VERSION "HIPBNYYYYYYYYYYYYYYYYYYYYYYYYYYYYYYYYYYYYY/4/%%%/4/'%**4YYY///"

NS_ :

BS_:

BU_: Equipment

BO_ 3221225472 VECTOR__INDEPENDENT_SIG_MSG: 0 Vector__XXX
 SG_ EngineExhaustGasRecirculation : 0|16@1+ (0.05,0) [0|3212.75] "kg/h" Vector__XXX
 SG_ ContlyMonitoredSyssEnabledComple : 0|8@1+ (8,0) [0|128] "" Vector__XXX

BO_ 257 CANSTD2: 8 Vector__XXX

BO_ 256 CANSTD1: 8 Vector__XXX
 SG_ STD1_sig : 0|2@1+ (1,0) [0|0] "" Vector__XXX

BO_ 2147483904 TC1: 8 Equipment
 SG_ DisengageDiffrlLockRqstRearAxle2 : 30|2@1+ (1,0) [0|3] "" Vector__XXX
 SG_ DisengageDiffrlLockRqstRearAxle1 : 28|2@1+ (1,0) [0|3] "" Vector__XXX
 SG_ DisengageDiffrlLockRqstFntAxle2 : 26|2@1+ (1,0) [0|3] "" Vector__XXX
 SG_ DisengageDiffrlLockRqstFntAxle1 : 24|2@1+ (1,0) [0|3] "" Vector__XXX
 SG_ DisengageDiffrlLockRqstCentrRear : 32|2@1+ (1,0) [0|3] "" Vector__XXX
 SG_ DisengageDiffrlLockRqstCentrFnt : 34|2@1+ (1,0) [0|3] "" Vector__XXX
 SG_ DisengageDiffrlLockRqstCentr : 36|2@1+ (1,0) [0|3] "" Vector__XXX
 SG_ TransmissionRequestedGear : 16|8@1+ (1,-125) [-125|125] "gear value" Vector__XXX
 SG_ RequestedPercentClutchSlip : 8|8@1+ (0.4,0) [0|100] "%" Vector__XXX
 SG_ TransReverseGearShiftInhibitRqst : 6|2@1+ (1,0) [0|3] "" Vector__XXX
 SG_ DisengageDrivelineRequest : 4|2@1+ (1,0) [0|3] "" Vector__XXX
 SG_ TransTrqCvtrLockupDisableRqst : 2|2@1+ (1,0) [0|3] "" Vector__XXX
 SG_ TransGearShiftInhibitRqst : 0|2@1+ (1,0) [0|3] "" Vector__XXX
 SG_ TransShiftSelectorDisplayModeSw : 54|2@1+ (1,0) [0|3] "" Vector__XXX
 SG_ TransmissionRequestedLaunchGear : 50|4@1+ (1,0) [0|15] "" Vector__XXX
 SG_ TransmissionMode8 : 62|2@1+ (1,0) [0|3] "" Vector__XXX
 SG_ TransmissionMode7 : 60|2@1+ (1,0) [0|3] "" Vector__XXX
 SG_ TransmissionMode6 : 58|2@1+ (1,0) [0|3] "" Vector__XXX
 SG_ TransmissionMode5 : 56|2@1+ (1,0) [0|3] "" Vector__XXX
 SG_ TransmissionMode4 : 46|2@1+ (1,0) [0|3] "" Vector__XXX
 SG_ TransmissionMode3 : 44|2@1+ (1,0) [0|3] "" Vector__XXX
 SG_ TransmissionMode2 : 42|2@1+ (1,0) [0|3] "" Vector__XXX
 SG_ TransmissionMode1 : 40|2@1+ (1,0) [0|3] "" Vector__XXX

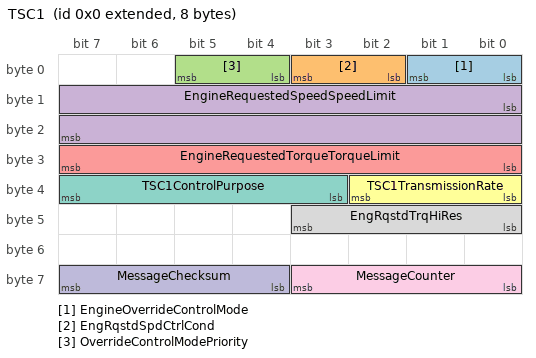
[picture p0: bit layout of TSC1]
BO_ 2147483648 TSC1: 8 Equipment
 SG_ EngineOverrideControlMode : 0|2@1+ (1,0) [0|3] "" Vector__XXX
 SG_ EngRqstdSpdCtrlCond : 2|2@1+ (1,0) [0|3] "" Vector__XXX
 SG_ OverrideControlModePriority : 4|2@1+ (1,0) [0|3] "" Vector__XXX
 SG_ EngineRequestedSpeedSpeedLimit : 8|16@1+ (1,0) [0|65535] "rpm" Vector__XXX
 SG_ EngineRequestedTorqueTorqueLimit : 24|8@1+ (1,-125) [-125|125] "%" Vector__XXX
 SG_ TSC1TransmissionRate : 32|3@1+ (1,0) [0|7] "" Vector__XXX
 SG_ TSC1ControlPurpose : 35|5@1+ (1,0) [0|31] "" Vector__XXX
 SG_ EngRqstdTrqHiRes : 40|4@1+ (1,0) [0|15] "%" Vector__XXX
 SG_ MessageCounter : 56|4@1+ (1,0) [0|15] "count" Vector__XXX
 SG_ MessageChecksum : 60|4@1+ (1,0) [0|15] "count" Vector__XXX

BO_ 2147537664 DM19: 20 Equipment
 SG_ CalibrationID4 : 128|32@1+ (1,0) [0|4294967295] "" Vector__XXX
 SG_ CalibrationID3 : 96|32@1+ (1,0) [0|4294967295] "" Vector__XXX
 SG_ CalibrationID2 : 64|32@1+ (1,0) [0|4294967295] "" Vector__XXX
 SG_ CalibrationID1 : 32|32@1+ (1,0) [0|4294967295] "" Vector__XXX
 SG_ CalibrationVerificationNumber : 0|32@1+ (1,0) [0|4294967295] "count" Vector__XXX

BO_ 2147522816 JLCM: 8 Equipment
 SG_ Joystick1Lamp1Command : 0|2@1+ (1,0) [0|3] "" Vector__XXX
 SG_ Joystick1Lamp2Command : 2|2@1+ (1,0) [0|3] "" Vector__XXX
 SG_ Joystick1Lamp3Command : 4|2@1+ (1,0) [0|3] "" Vector__XXX
 SG_ Joystick1Lamp4Command : 6|2@1+ (1,0) [0|3] "" Vector__XXX
 SG_ Joystick1Lamp5Command : 8|2@1+ (1,0) [0|3] "" Vector__XXX
 SG_ Joystick1Lamp6Command : 10|2@1+ (1,0) [0|3] "" Vector__XXX
 SG_ Joystick1Lamp7Command : 12|2@1+ (1,0) [0|3] "" Vector__XXX
 SG_ Joystick1Lamp8Command : 14|2@1+ (1,0) [0|3] "" Vector__XXX
 SG_ Joystick1Lamp9Command : 16|2@1+ (1,0) [0|3] "" Vector__XXX
 SG_ Joystick1Lamp10Command : 18|2@1+ (1,0) [0|3] "" Vector__XXX
 SG_ Joystick2Lamp1Command : 20|2@1+ (1,0) [0|3] "" Vector__XXX
 SG_ Joystick2Lamp2Command : 22|2@1+ (1,0) [0|3] "" Vector__XXX
 SG_ Joystick2Lamp3Command : 24|2@1+ (1,0) [0|3] "" Vector__XXX
 SG_ Joystick2Lamp4Command : 26|2@1+ (1,0) [0|3] "" Vector__XXX
 SG_ Joystick2Lamp5Command : 28|2@1+ (1,0) [0|3] "" Vector__XXX
 SG_ Joystick2Lamp6Command : 30|2@1+ (1,0) [0|3] "" Vector__XXX
 SG_ Joystick2Lamp7Command : 32|2@1+ (1,0) [0|3] "" Vector__XXX
 SG_ Joystick2Lamp8Command : 34|2@1+ (1,0) [0|3] "" Vector__XXX
 SG_ Joystick2Lamp9Command : 36|2@1+ (1,0) [0|3] "" Vector__XXX
 SG_ Joystick2Lamp10Command : 38|2@1+ (1,0) [0|3] "" Vector__XXX
 SG_ Joystick3Lamp1Command : 40|2@1+ (1,0) [0|3] "" Vector__XXX
 SG_ Joystick3Lamp2Command : 42|2@1+ (1,0) [0|3] "" Vector__XXX
 SG_ Joystick3Lamp3Command : 44|2@1+ (1,0) [0|3] "" Vector__XXX
 SG_ Joystick3Lamp4Command : 46|2@1+ (1,0) [0|3] "" Vector__XXX
 SG_ Joystick3Lamp5Command : 48|2@1+ (1,0) [0|3] "" Vector__XXX
 SG_ Joystick3Lamp6Command : 50|2@1+ (1,0) [0|3] "" Vector__XXX
 SG_ Joystick3Lamp7Command : 52|2@1+ (1,0) [0|3] "" Vector__XXX
 SG_ Joystick3Lamp8Command : 54|2@1+ (1,0) [0|3] "" Vector__XXX
 SG_ Joystick3Lamp9Command : 56|2@1+ (1,0) [0|3] "" Vector__XXX
 SG_ Joystick3Lamp10Command : 58|2@1+ (1,0) [0|3] "" Vector__XXX

BO_ 2147548747 TCFG2: 2 Equipment
 SG_ TransmissionTorqueLimit : 0|16@1+ (1,0) [0|64255] "Nm" Vector__XXX

BO_ 2147548899 EC1: 39 Equipment
 SG_ EngineSpeedAtIdlePoint1 : 0|16@1+ (0.125,0) [0|8031.875] "rpm" Vector__XXX
 SG_ EnginePercentTorqueAtIdlePoint1 : 16|8@1+ (1,-125) [-125|125] "%" Vector__XXX
 SG_ EngineSpeedAtPoint2 : 24|16@1+ (0.125,0) [0|8031.875] "rpm" Vector__XXX
 SG_ EnginePercentTorqueAtPoint2 : 40|8@1+ (1,-125) [-125|125] "%" Vector__XXX
 SG_ EngineSpeedAtPoint3 : 48|16@1+ (0.125,0) [0|8031.875] "rpm" Vector__XXX
 SG_ EnginePercentTorqueAtPoint3 : 64|8@1+ (1,-125) [-125|125] "%" Vector__XXX
 SG_ EngineSpeedAtPoint4 : 72|16@1+ (0.125,0) [0|8031.875] "rpm" Vector__XXX
 SG_ EnginePercentTorqueAtPoint4 : 88|8@1+ (1,-125) [-125|125] "%" Vector__XXX
 SG_ EngineSpeedAtPoint5 : 96|16@1+ (0.125,0) [0|8031.875] "rpm" Vector__XXX
 SG_ EnginePercentTorqueAtPoint5 : 112|8@1+ (1,-125) [-125|125] "%" Vector__XXX
 SG_ EngineSpeedAtHighIdlePoint6 : 120|16@1+ (0.125,0) [0|8031.875] "rpm" Vector__XXX
 SG_ EngineGain : 136|16@1+ (0.00078125,0) [0|50.2] "%/rpm" Vector__XXX
 SG_ EngineReferenceTorque : 152|16@1+ (1,0) [0|64255] "Nm" Vector__XXX
 SG_ EngMaxMomentaryOverrideSpdPoint7 : 168|16@1+ (0.125,0) [0|8031.875] "rpm" Vector__XXX
 SG_ EngMaxMomentaryOverrideTimeLmt : 184|8@1+ (0.1,0) [0|25] "Seconds" Vector__XXX
 SG_ EngRqstdSpdCtrlRngLowerLmt : 192|8@1+ (10,0) [0|2500] "rpm" Vector__XXX
 SG_ EngRqstdSpdCtrlRngUpperLmt : 200|8@1+ (10,0) [0|2500] "rpm" Vector__XXX
 SG_ EngRqstdTrqCtrlRngLowerLmt : 208|8@1+ (1,-125) [-125|125] "%" Vector__XXX
 SG_ EngRqstdTrqCtrlRngUpperLmt : 216|8@1+ (1,-125) [-125|125] "%" Vector__XXX
 SG_ EngineMomentOfInertia : 240|16@1+ (0.004,0) [0|257.02] "kg/m²" Vector__XXX
 SG_ EngineDefaultTorqueLimit : 256|16@1+ (1,0) [0|64255] "Nm" Vector__XXX
 SG_ SupportVariableRateTSC1Message : 272|8@1+ (1,0) [0|255] "" Vector__XXX
 SG_ SupportTSC1ControlPurposeGroup1 : 280|8@1+ (1,0) [0|255] "" Vector__XXX
 SG_ SupportTSC1ControlPurposeGroup2 : 288|8@1+ (1,0) [0|255] "" Vector__XXX
 SG_ SupportTSC1ControlPurposeGroup3 : 296|8@1+ (1,0) [0|255] "" Vector__XXX
 SG_ SupportTSC1ControlPurposeGroup4 : 304|8@1+ (1,0) [0|255] "" Vector__XXX

CM_ BO_ 3221225472 "This is a message for not used signals, created by Vector CANdb++ DBC OLE DB Provider.";
CM_ SG_ 3221225472 EngineExhaustGasRecirculation "Engine Exhaust Gas Recirculation: Flow rate of gas through the EGR system.Engine Exhaust Gas Recirculation: Desired percentage of maximum Exhaust Gas Recirculation (EGR) valve opening for valve 2.Engine Exhaust Gas Recirculation: Exhaust Gas Recirculation (EGR) Temperature measured at the EGR cooler inlet.Engine Exhaust Gas Recirculation: Exhaust Gas Recirculation gas absolute pressure is measured at the EGR cooler inlet.Engine Exhaust Gas Recirculation: Exhaust Gas Recirculation cooler efficiency is an indication of the cooler's ability to reduce the temperature of the exhaust gas that is being recirculated back to the intake.Engine Exhaust Gas Recirculation: Desired percentage of maximum Exhaust Gas Recirculation (EGR) valve opening.";
CM_ SG_ 3221225472 ContlyMonitoredSyssEnabledComple "Continuously Monitored Systems Enabled/Completed Status: This parameter identifies the continuously monitored system enable/completed support and status.";
CM_ BO_ 257 "Msg without signal";
CM_ BO_ 2147483904 "Transmission Control 1";
CM_ SG_ 2147483904 DisengageDiffrlLockRqstRearAxle2 "Disengage Differential Lock Request - Rear Axle 2: Command signal used to disengage the various differential locks, e.";
CM_ SG_ 2147483904 DisengageDiffrlLockRqstRearAxle1 "Disengage Differential Lock Request - Rear Axle 1: Command signal used to disengage the various differential locks, e.";
CM_ SG_ 2147483904 DisengageDiffrlLockRqstFntAxle2 "Disengage Differential Lock Request - Front Axle 2: Command signal used to disengage the various differential locks, e.";
CM_ SG_ 2147483904 DisengageDiffrlLockRqstFntAxle1 "Disengage Differential Lock Request - Front Axle 1: Command signal used to disengage the various differential locks, e.";
CM_ SG_ 2147483904 DisengageDiffrlLockRqstCentrRear "Disengage Differential Lock Request - Central Rear: Command signal used to disengage the various differential locks, e.";
CM_ SG_ 2147483904 DisengageDiffrlLockRqstCentrFnt "Disengage Differential Lock Request - Central Front: Command signal used to disengage the various differential locks, e.";
CM_ SG_ 2147483904 DisengageDiffrlLockRqstCentr "Disengage Differential Lock Request - Central: Command signal used to disengage the various differential locks, e.";
CM_ SG_ 2147483904 TransmissionRequestedGear "Transmission Requested Gear: Gear requested by the operator, ABS, or engine.";
CM_ SG_ 2147483904 RequestedPercentClutchSlip "Requested Percent Clutch Slip: Parameter which represents the percent clutch slip requested by a device.";
CM_ SG_ 2147483904 TransReverseGearShiftInhibitRqst "Transmission Reverse Gear Shift Inhibit Request: Allows devices external to the normal transmission shift selector system to request the transmission to inhibit shifts into any Reverse gear and force the transmission into Neutral if it is currently in Reverse or attempting to shift to Reverse.";
CM_ SG_ 2147483904 DisengageDrivelineRequest "Disengage Driveline Request: Command signal used to simply disengage the driveline, e.";
CM_ SG_ 2147483904 TransTrqCvtrLockupDisableRqst "Transmission Torque Converter Lockup Disable Request: Command signal to prevent torque converter lockup, which may cause problems in certain circumstances for ASR.";
CM_ SG_ 2147483904 TransGearShiftInhibitRqst "Transmission Gear Shift Inhibit Request: Command signal to inhibit gear shifts.";
CM_ SG_ 2147483904 TransShiftSelectorDisplayModeSw "Transmission Shift Selector Display Mode Switch: Status of the operator's switch used to 'toggle' through multiple display modes of a shift selector display.";
CM_ SG_ 2147483904 TransmissionRequestedLaunchGear "Transmission Requested Launch Gear: Initial gear for the transmission to start out in when the vehicle is launched from a standing stop, as specified by the vehicle operator or vehicle system.";
CM_ SG_ 2147483904 TransmissionMode8 "Transmission Mode 8: Indicates whether transmission mode 8 is enabled.";
CM_ SG_ 2147483904 TransmissionMode7 "Transmission Mode 7: Indicates whether transmission mode 7 is enabled.";
CM_ SG_ 2147483904 TransmissionMode6 "Transmission Mode 6: Indicates whether transmission mode 6 is enabled.";
CM_ SG_ 2147483904 TransmissionMode5 "Transmission Mode 5: Indicates whether transmission mode 5 is enabled.";
CM_ SG_ 2147483904 TransmissionMode4 "Transmission Mode 4: Indicates whether transmission mode 4 is enabled.";
CM_ SG_ 2147483904 TransmissionMode3 "Transmission Mode 3: Indicates whether transmission mode 3 is enabled.";
CM_ SG_ 2147483904 TransmissionMode2 "Transmission Mode 2: Indicates whether transmission mode 2 is enabled.";
CM_ SG_ 2147483904 TransmissionMode1 "Transmission Mode 1: Indicates whether transmission mode 1 is enabled.";
CM_ BO_ 2147483648 "Torque/Speed Control 1";
CM_ SG_ 2147483648 EngineOverrideControlMode "Engine Override Control Mode: The override control mode defines which sort of command is used:";
CM_ SG_ 2147483648 EngRqstdSpdCtrlCond "Engine Requested Speed Control Conditions: This mode tells the engine control system the governor characteristics that are desired during speed control.";
CM_ SG_ 2147483648 OverrideControlModePriority "Override Control Mode Priority: This field is used as an input to the engine or retarder to determine the priority of the Override Control Mode received in the Torque/Speed Control message (see PGN 0).";
CM_ SG_ 2147483648 EngineRequestedSpeedSpeedLimit "Engine Requested Speed/Speed Limit: Parameter provided to the engine from external sources in the torque/speed control message.";
CM_ SG_ 2147483648 EngineRequestedTorqueTorqueLimit "Engine Requested Torque/Torque Limit: Parameter provided to the engine or retarder in the torque/speed control message for controlling or limiting the output torque.";
CM_ SG_ 2147483648 TSC1TransmissionRate "TSC1 Transmission Rate: This parameter indicates the transmission rate at which the sending device will transmit the TSC1 message.";
CM_ SG_ 2147483648 TSC1ControlPurpose "TSC1 Control Purpose: State signal which indicates which control mode the sending device is using to generate the TSC1 command.";
CM_ SG_ 2147483648 EngRqstdTrqHiRes "Engine Requested Torque -  High Resolution: This parameter displays an additional torque in percent of the reference engine torque.";
CM_ SG_ 2147483648 MessageCounter "Message Counter: The message counter is used to detect situations where the transmitting ECU malfunction repeats the same frame all the time.";
CM_ SG_ 2147483648 MessageChecksum "Message Checksum: The checksum is used to verify the signal path from the transmitting device to the receiving device.";
CM_ BO_ 2147537664 "Calibration Information";
CM_ SG_ 2147537664 CalibrationVerificationNumber "Calibration Verification Number: Checksum of entire calibration, including code and data.";
CM_ BO_ 2147522816 "Joystick Lamp Command Message";
CM_ SG_ 2147522816 Joystick1Lamp1Command "Joystick 1 Lamp 1 Command: Tells joystick 1 to switch on/off/blinking lamp 1.";
CM_ SG_ 2147522816 Joystick1Lamp2Command "Joystick 1 Lamp 2 Command: Tells joystick 1 to switch on/off/blinking lamp 2.";
CM_ SG_ 2147522816 Joystick1Lamp3Command "Joystick 1 Lamp 3 Command: Tells joystick 1 to switch on/off/blinking lamp 3.";
CM_ SG_ 2147522816 Joystick1Lamp4Command "Joystick 1 Lamp 4 Command: Tells joystick 1 to switch on/off/blinking lamp 4.";
CM_ SG_ 2147522816 Joystick1Lamp5Command "Joystick 1 Lamp 5 Command: Tells joystick 1 to switch on/off/blinking lamp 5.";
CM_ SG_ 2147522816 Joystick1Lamp6Command "Joystick 1 Lamp 6 Command: Tells joystick 1 to switch on/off/blinking lamp 6.";
CM_ SG_ 2147522816 Joystick1Lamp7Command "Joystick 1 Lamp 7 Command: Tells joystick 1 to switch on/off/blinking lamp 7.";
CM_ SG_ 2147522816 Joystick1Lamp8Command "Joystick 1 Lamp 8 Command: Tells joystick 1 to switch on/off/blinking lamp 8.";
CM_ SG_ 2147522816 Joystick1Lamp9Command "Joystick 1 Lamp 9 Command: Tells joystick 1 to switch on/off/blinking lamp 9.";
CM_ SG_ 2147522816 Joystick1Lamp10Command "Joystick 1 Lamp 10 Command: Tells joystick 1 to switch on/off/blinking lamp 10.";
CM_ SG_ 2147522816 Joystick2Lamp1Command "Joystick 2 Lamp 1 Command: Tells joystick 2 to switch on/off/blinking lamp 1.";
CM_ SG_ 2147522816 Joystick2Lamp2Command "Joystick 2 Lamp 2 Command: Tells joystick 2 to switch on/off/blinking lamp 2.";
CM_ SG_ 2147522816 Joystick2Lamp3Command "Joystick 2 Lamp 3 Command: Tells joystick 2 to switch on/off/blinking lamp 3.";
CM_ SG_ 2147522816 Joystick2Lamp4Command "Joystick 2 Lamp 4 Command: Tells joystick 2 to switch on/off/blinking lamp 4.";
CM_ SG_ 2147522816 Joystick2Lamp5Command "Joystick 2 Lamp 5 Command: Tells joystick 2 to switch on/off/blinking lamp 5.";
CM_ SG_ 2147522816 Joystick2Lamp6Command "Joystick 2 Lamp 6 Command: Tells joystick 2 to switch on/off/blinking lamp 6.";
CM_ SG_ 2147522816 Joystick2Lamp7Command "Joystick 2 Lamp 7 Command: Tells joystick 2 to switch on/off/blinking lamp 7.";
CM_ SG_ 2147522816 Joystick2Lamp8Command "Joystick 2 Lamp 8 Command: Tells joystick 2 to switch on/off/blinking lamp 8.";
CM_ SG_ 2147522816 Joystick2Lamp9Command "Joystick 2 Lamp 9 Command: Tells joystick 2 to switch on/off/blinking lamp 9.";
CM_ SG_ 2147522816 Joystick2Lamp10Command "Joystick 2 Lamp 10 Command: Tells joystick 2 to switch on/off/blinking lamp 10.";
CM_ SG_ 2147522816 Joystick3Lamp1Command "Joystick 3 Lamp 1 Command: Tells joystick 3 to switch on/off/blinking lamp 1.";
CM_ SG_ 2147522816 Joystick3Lamp2Command "Joystick 3 Lamp 2 Command: Tells joystick 3 to switch on/off/blinking lamp 2.";
CM_ SG_ 2147522816 Joystick3Lamp3Command "Joystick 3 Lamp 3 Command: Tells joystick 3 to switch on/off/blinking lamp 3.";
CM_ SG_ 2147522816 Joystick3Lamp4Command "Joystick 3 Lamp 4 Command: Tells joystick 3 to switch on/off/blinking lamp 4.";
CM_ SG_ 2147522816 Joystick3Lamp5Command "Joystick 3 Lamp 5 Command: Tells joystick 3 to switch on/off/blinking lamp 5.";
CM_ SG_ 2147522816 Joystick3Lamp6Command "Joystick 3 Lamp 6 Command: Tells joystick 3 to switch on/off/blinking lamp 6.";
CM_ SG_ 2147522816 Joystick3Lamp7Command "Joystick 3 Lamp 7 Command: Tells joystick 3 to switch on/off/blinking lamp 7.";
CM_ SG_ 2147522816 Joystick3Lamp8Command "Joystick 3 Lamp 8 Command: Tells joystick 3 to switch on/off/blinking lamp 8.";
CM_ SG_ 2147522816 Joystick3Lamp9Command "Joystick 3 Lamp 9 Command: Tells joystick 3 to switch on/off/blinking lamp 9.";
CM_ SG_ 2147522816 Joystick3Lamp10Command "Joystick 3 Lamp 10 Command: Tells joystick 3 to switch on/off/blinking lamp 10.";
CM_ BO_ 2147548747 "Transmission Configuration 2";
CM_ SG_ 2147548747 TransmissionTorqueLimit "Transmission Torque Limit: Parameter provided to the engine from the transmission as a torque limit to be invoked by the engine in the event that J1939 communication with the transmission is lost.";
CM_ BO_ 2147548899 "Engine Configuration 1";
CM_ SG_ 2147548899 EngineSpeedAtIdlePoint1 "Engine Speed At Idle, Point 1: Stationary low idle speed of engine which includes influences due to engine temperature (after power up) and other stationary changes (calibration offsets, sensor failures, etc).";
CM_ SG_ 2147548899 EnginePercentTorqueAtIdlePoint1 "Engine Percent Torque At Idle, Point 1: The torque limit that indicates the available engine torque which can be provided by the engine at idle speed.";
CM_ SG_ 2147548899 EngineSpeedAtPoint2 "Engine Speed At Point 2: Engine speed of point 2 of the engine torque map (see PGN 65251 and supporting document).";
CM_ SG_ 2147548899 EnginePercentTorqueAtPoint2 "Engine Percent Torque At Point 2: The torque limit that indicates the available engine torque which can be provided by the engine at point 2 of the engine map (see PGN 65251 and supporting documents).";
CM_ SG_ 2147548899 EngineSpeedAtPoint3 "Engine Speed At Point 3: Engine speed of point 3, 4, and 5 of the engine torque map (see PGN 65251 and supporting document).";
CM_ SG_ 2147548899 EnginePercentTorqueAtPoint3 "Engine Percent Torque At Point 3: The torque limit that indicates the available engine torque which can be provided by the engine at point 3, 4, and 5 of the engine map (see PGN 65251 and supporting documents).";
CM_ SG_ 2147548899 EngineSpeedAtPoint4 "Engine Speed At Point 4: Engine speed of point 3, 4, and 5 of the engine torque map (see PGN 65251 and supporting document).";
CM_ SG_ 2147548899 EnginePercentTorqueAtPoint4 "Engine Percent Torque At Point 4: The torque limit that indicates the available engine torque which can be provided by the engine at point 3, 4, and 5 of the engine map (see PGN 65251 and supporting documents).";
CM_ SG_ 2147548899 EngineSpeedAtPoint5 "Engine Speed At Point 5: Engine speed of point 3, 4, and 5 of the engine torque map (see PGN 65251 and supporting document).";
CM_ SG_ 2147548899 EnginePercentTorqueAtPoint5 "Engine Percent Torque At Point 5: The torque limit that indicates the available engine torque which can be provided by the engine at point 3, 4, and 5 of the engine map (see PGN 65251 and supporting documents).";
CM_ SG_ 2147548899 EngineSpeedAtHighIdlePoint6 "Engine Speed At High Idle, Point 6: Engine speed of high idle (point 6) of the engine torque map (see PGN 65251 and supporting document).";
CM_ SG_ 2147548899 EngineGain "Engine Gain: The endspeed governor is defined as a linear line with the following equations (Capital letters mean physical values, small letters mean normalized values).";
CM_ SG_ 2147548899 EngineReferenceTorque "Engine Reference Torque: This parameter is the 100% reference value for all defined indicated engine torque parameters.";
CM_ SG_ 2147548899 EngMaxMomentaryOverrideSpdPoint7 "Engine Maximum Momentary Override Speed, Point 7: The maximum engine speed above high idle allowed by the engine control during a momentary high idle override.";
CM_ SG_ 2147548899 EngMaxMomentaryOverrideTimeLmt "Engine Maximum Momentary Override Time Limit: The maximum time limit allowed to override the engine's high idle speed.";
CM_ SG_ 2147548899 EngRqstdSpdCtrlRngLowerLmt "Engine Requested Speed Control Range Lower Limit: The minimum engine speed that the engine will allow when operating in a speed control/limit mode.";
CM_ SG_ 2147548899 EngRqstdSpdCtrlRngUpperLmt "Engine Requested Speed Control Range Upper Limit: The maximum engine speed regardless of load that the engine will allow when operating in a speed control/limit mode, excluding any maximum momentary engine override speed, if supported.";
CM_ SG_ 2147548899 EngRqstdTrqCtrlRngLowerLmt "Engine Requested Torque Control Range Lower Limit: The minimum engine torque that the engine will allow when operating in a torque control/limit mode.";
CM_ SG_ 2147548899 EngRqstdTrqCtrlRngUpperLmt "Engine Requested Torque Control Range Upper Limit: The maximum engine torque that the engine will allow when operating in a torque control/limit mode.";
CM_ SG_ 2147548899 EngineMomentOfInertia "Engine Moment Of Inertia: Moment of inertia for the engine, including items driven full-time by the engine such as fuel, oil and cooling pumps.";
CM_ SG_ 2147548899 EngineDefaultTorqueLimit "Engine Default Torque Limit: Companion parameter to Transmission Torque Limit (SPN 1845).";
CM_ SG_ 2147548899 SupportVariableRateTSC1Message "Support Variable Rate TSC1 Message: This parameter indicates which TSC1 transmission rates are supported by the engine ECU in addition to the required 10ms transmission rate for temporary powertrain control purposes.";
CM_ SG_ 2147548899 SupportTSC1ControlPurposeGroup1 "Support TSC1 Control Purpose Group 1: This parameter indicates which TSC1 control purposes are supported in group 1 of 4.";
CM_ SG_ 2147548899 SupportTSC1ControlPurposeGroup2 "Support TSC1 Control Purpose Group 2: This parameter indicates which TSC1 control purposes are supported in group 2 of 4.";
CM_ SG_ 2147548899 SupportTSC1ControlPurposeGroup3 "Support TSC1 Control Purpose Group 3: This parameter indicates which TSC1 control purposes are supported in group 3 of 4.";
CM_ SG_ 2147548899 SupportTSC1ControlPurposeGroup4 "Support TSC1 Control Purpose Group 4: This parameter indicates which TSC1 control purposes are supported in group 4 of 4.";
BA_DEF_  "J1939PGN" INT 0 1;
BA_DEF_  "InputFile" STRING ;
BA_DEF_ BO_  "PGNDoc" STRING ;
BA_DEF_ BO_  "J1939PGRepetitionCycle" INT 0 65535;
BA_DEF_ BO_  "J1939PGRepetitionType" ENUM  "always","when active","on request";
BA_DEF_ SG_  "SigType" STRING ;
BA_DEF_ SG_  "SPN" INT 0 16777215;
BA_DEF_ SG_  "SPNDoc" STRING ;
BA_DEF_ SG_  "StatusOfSPN" STRING ;
BA_DEF_ SG_  "DateSPNwasAddedToPGN" STRING ;
BA_DEF_ SG_  "StatusOfSPNAdditionToPGN" STRING ;
BA_DEF_ SG_  "DateSPNWasAddedModified" STRING ;
BA_DEF_ SG_  "SystemSignalLongSymbol" STRING ;
BA_DEF_DEF_  "J1939PGN" 0;
BA_DEF_DEF_  "InputFile" "";
BA_DEF_DEF_  "PGNDoc" "";
BA_DEF_DEF_  "J1939PGRepetitionCycle" 100;
BA_DEF_DEF_  "J1939PGRepetitionType" "always";
BA_DEF_DEF_  "SigType" "";
BA_DEF_DEF_  "SPN" 0;
BA_DEF_DEF_  "SPNDoc" "";
BA_DEF_DEF_  "StatusOfSPN" "";
BA_DEF_DEF_  "DateSPNwasAddedToPGN" "";
BA_DEF_DEF_  "StatusOfSPNAdditionToPGN" "";
BA_DEF_DEF_  "DateSPNWasAddedModified" "";
BA_DEF_DEF_  "SystemSignalLongSymbol" "";
BA_ "InputFile" "Companion spreadsheet thru 4Q2007 Draft.xls:4Q2007";
BA_ "J1939PGN" 1;
BA_ "J1939PGRepetitionCycle" BO_ 2147483648 10;
BA_ "PGNDoc" BO_ 2147483648 "J1939-71";
BA_ "J1939PGRepetitionCycle" BO_ 2147537664 0;
BA_ "J1939PGRepetitionType" BO_ 2147537664 2;
BA_ "PGNDoc" BO_ 2147537664 "J1939-73";
BA_ "J1939PGRepetitionCycle" BO_ 2147522816 5000;
BA_ "PGNDoc" BO_ 2147522816 "J1939-71";
BA_ "J1939PGRepetitionCycle" BO_ 2147548747 0;
BA_ "J1939PGRepetitionType" BO_ 2147548747 2;
BA_ "PGNDoc" BO_ 2147548747 "J1939-71";
BA_ "J1939PGRepetitionCycle" BO_ 2147548899 500;
BA_ "PGNDoc" BO_ 2147548899 "J1939-71";
BA_ "DateSPNWasAddedModified" SG_ 3221225472 EngineExhaustGasRecirculation "11/30/2003";
BA_ "DateSPNwasAddedToPGN" SG_ 3221225472 EngineExhaustGasRecirculation "24-Oct-01";
BA_ "StatusOfSPNAdditionToPGN" SG_ 3221225472 EngineExhaustGasRecirculation "Published";
BA_ "StatusOfSPN" SG_ 3221225472 EngineExhaustGasRecirculation "Published";
BA_ "SPNDoc" SG_ 3221225472 EngineExhaustGasRecirculation "J1939-71";
BA_ "SPN" SG_ 3221225472 EngineExhaustGasRecirculation 2791;
BA_ "SigType" SG_ 3221225472 ContlyMonitoredSyssEnabledComple "BIT-MAPPED";
BA_ "DateSPNWasAddedModified" SG_ 3221225472 ContlyMonitoredSyssEnabledComple "3/10/2004";
BA_ "DateSPNwasAddedToPGN" SG_ 3221225472 ContlyMonitoredSyssEnabledComple "10-Apr-04";
BA_ "StatusOfSPNAdditionToPGN" SG_ 3221225472 ContlyMonitoredSyssEnabledComple "Published";
BA_ "StatusOfSPN" SG_ 3221225472 ContlyMonitoredSyssEnabledComple "Published";
BA_ "SPNDoc" SG_ 3221225472 ContlyMonitoredSyssEnabledComple "J1939-73";
BA_ "SPN" SG_ 3221225472 ContlyMonitoredSyssEnabledComple 3303;
BA_ "SystemSignalLongSymbol" SG_ 3221225472 ContlyMonitoredSyssEnabledComple "ContlyMonitoredSyssEnabledCompletedStat";
BA_ "DateSPNwasAddedToPGN" SG_ 2147483904 DisengageDiffrlLockRqstRearAxle2 "01-Oct-98";
BA_ "StatusOfSPNAdditionToPGN" SG_ 2147483904 DisengageDiffrlLockRqstRearAxle2 "Published";
BA_ "StatusOfSPN" SG_ 2147483904 DisengageDiffrlLockRqstRearAxle2 "Published";
BA_ "SPNDoc" SG_ 2147483904 DisengageDiffrlLockRqstRearAxle2 "J1939-71";
BA_ "SPN" SG_ 2147483904 DisengageDiffrlLockRqstRearAxle2 688;
BA_ "DateSPNwasAddedToPGN" SG_ 2147483904 DisengageDiffrlLockRqstRearAxle1 "01-Oct-98";
BA_ "StatusOfSPNAdditionToPGN" SG_ 2147483904 DisengageDiffrlLockRqstRearAxle1 "Published";
BA_ "StatusOfSPN" SG_ 2147483904 DisengageDiffrlLockRqstRearAxle1 "Published";
BA_ "SPNDoc" SG_ 2147483904 DisengageDiffrlLockRqstRearAxle1 "J1939-71";
BA_ "SPN" SG_ 2147483904 DisengageDiffrlLockRqstRearAxle1 687;
BA_ "DateSPNwasAddedToPGN" SG_ 2147483904 DisengageDiffrlLockRqstFntAxle2 "01-Oct-98";
BA_ "StatusOfSPNAdditionToPGN" SG_ 2147483904 DisengageDiffrlLockRqstFntAxle2 "Published";
BA_ "StatusOfSPN" SG_ 2147483904 DisengageDiffrlLockRqstFntAxle2 "Published";
BA_ "SPNDoc" SG_ 2147483904 DisengageDiffrlLockRqstFntAxle2 "J1939-71";
BA_ "SPN" SG_ 2147483904 DisengageDiffrlLockRqstFntAxle2 686;
BA_ "DateSPNwasAddedToPGN" SG_ 2147483904 DisengageDiffrlLockRqstFntAxle1 "01-Oct-98";
BA_ "StatusOfSPNAdditionToPGN" SG_ 2147483904 DisengageDiffrlLockRqstFntAxle1 "Published";
BA_ "StatusOfSPN" SG_ 2147483904 DisengageDiffrlLockRqstFntAxle1 "Published";
BA_ "SPNDoc" SG_ 2147483904 DisengageDiffrlLockRqstFntAxle1 "J1939-71";
BA_ "SPN" SG_ 2147483904 DisengageDiffrlLockRqstFntAxle1 685;
BA_ "DateSPNwasAddedToPGN" SG_ 2147483904 DisengageDiffrlLockRqstCentrRear "01-Oct-98";
BA_ "StatusOfSPNAdditionToPGN" SG_ 2147483904 DisengageDiffrlLockRqstCentrRear "Published";
BA_ "StatusOfSPN" SG_ 2147483904 DisengageDiffrlLockRqstCentrRear "Published";
BA_ "SPNDoc" SG_ 2147483904 DisengageDiffrlLockRqstCentrRear "J1939-71";
BA_ "SPN" SG_ 2147483904 DisengageDiffrlLockRqstCentrRear 691;
BA_ "DateSPNwasAddedToPGN" SG_ 2147483904 DisengageDiffrlLockRqstCentrFnt "01-Oct-98";
BA_ "StatusOfSPNAdditionToPGN" SG_ 2147483904 DisengageDiffrlLockRqstCentrFnt "Published";
BA_ "StatusOfSPN" SG_ 2147483904 DisengageDiffrlLockRqstCentrFnt "Published";
BA_ "SPNDoc" SG_ 2147483904 DisengageDiffrlLockRqstCentrFnt "J1939-71";
BA_ "SPN" SG_ 2147483904 DisengageDiffrlLockRqstCentrFnt 690;
BA_ "DateSPNwasAddedToPGN" SG_ 2147483904 DisengageDiffrlLockRqstCentr "01-Oct-98";
BA_ "StatusOfSPNAdditionToPGN" SG_ 2147483904 DisengageDiffrlLockRqstCentr "Published";
BA_ "StatusOfSPN" SG_ 2147483904 DisengageDiffrlLockRqstCentr "Published";
BA_ "SPNDoc" SG_ 2147483904 DisengageDiffrlLockRqstCentr "J1939-71";
BA_ "SPN" SG_ 2147483904 DisengageDiffrlLockRqstCentr 689;
BA_ "DateSPNWasAddedModified" SG_ 2147483904 TransmissionRequestedGear "11/20/2003";
BA_ "DateSPNwasAddedToPGN" SG_ 2147483904 TransmissionRequestedGear "09-Nov-00";
BA_ "StatusOfSPNAdditionToPGN" SG_ 2147483904 TransmissionRequestedGear "Published";
BA_ "StatusOfSPN" SG_ 2147483904 TransmissionRequestedGear "Published";
BA_ "SPNDoc" SG_ 2147483904 TransmissionRequestedGear "J1939-71";
BA_ "SPN" SG_ 2147483904 TransmissionRequestedGear 525;
BA_ "DateSPNwasAddedToPGN" SG_ 2147483904 RequestedPercentClutchSlip "01-Oct-98";
BA_ "StatusOfSPNAdditionToPGN" SG_ 2147483904 RequestedPercentClutchSlip "Published";
BA_ "StatusOfSPN" SG_ 2147483904 RequestedPercentClutchSlip "Published";
BA_ "SPNDoc" SG_ 2147483904 RequestedPercentClutchSlip "J1939-71";
BA_ "SPN" SG_ 2147483904 RequestedPercentClutchSlip 684;
BA_ "DateSPNWasAddedModified" SG_ 2147483904 TransReverseGearShiftInhibitRqst "2/21/2007";
BA_ "DateSPNwasAddedToPGN" SG_ 2147483904 TransReverseGearShiftInhibitRqst "21-Feb-07";
BA_ "StatusOfSPNAdditionToPGN" SG_ 2147483904 TransReverseGearShiftInhibitRqst "Published";
BA_ "StatusOfSPN" SG_ 2147483904 TransReverseGearShiftInhibitRqst "Published";
BA_ "SPNDoc" SG_ 2147483904 TransReverseGearShiftInhibitRqst "J1939-71";
BA_ "SPN" SG_ 2147483904 TransReverseGearShiftInhibitRqst 4242;
BA_ "DateSPNwasAddedToPGN" SG_ 2147483904 DisengageDrivelineRequest "01-Oct-98";
BA_ "StatusOfSPNAdditionToPGN" SG_ 2147483904 DisengageDrivelineRequest "Published";
BA_ "StatusOfSPN" SG_ 2147483904 DisengageDrivelineRequest "Published";
BA_ "SPNDoc" SG_ 2147483904 DisengageDrivelineRequest "J1939-71";
BA_ "SPN" SG_ 2147483904 DisengageDrivelineRequest 683;
BA_ "DateSPNwasAddedToPGN" SG_ 2147483904 TransTrqCvtrLockupDisableRqst "01-Oct-98";
BA_ "StatusOfSPNAdditionToPGN" SG_ 2147483904 TransTrqCvtrLockupDisableRqst "Published";
BA_ "StatusOfSPN" SG_ 2147483904 TransTrqCvtrLockupDisableRqst "Published";
BA_ "SPNDoc" SG_ 2147483904 TransTrqCvtrLockupDisableRqst "J1939-71";
BA_ "SPN" SG_ 2147483904 TransTrqCvtrLockupDisableRqst 682;
BA_ "DateSPNWasAddedModified" SG_ 2147483904 TransGearShiftInhibitRqst "12/25/2003";
BA_ "DateSPNwasAddedToPGN" SG_ 2147483904 TransGearShiftInhibitRqst "01-Oct-98";
BA_ "StatusOfSPNAdditionToPGN" SG_ 2147483904 TransGearShiftInhibitRqst "Published";
BA_ "StatusOfSPN" SG_ 2147483904 TransGearShiftInhibitRqst "Published";
BA_ "SPNDoc" SG_ 2147483904 TransGearShiftInhibitRqst "J1939-71";
BA_ "SPN" SG_ 2147483904 TransGearShiftInhibitRqst 681;
BA_ "DateSPNWasAddedModified" SG_ 2147483904 TransShiftSelectorDisplayModeSw "2/20/2003";
BA_ "DateSPNwasAddedToPGN" SG_ 2147483904 TransShiftSelectorDisplayModeSw "20-Feb-03";
BA_ "StatusOfSPNAdditionToPGN" SG_ 2147483904 TransShiftSelectorDisplayModeSw "Published";
BA_ "StatusOfSPN" SG_ 2147483904 TransShiftSelectorDisplayModeSw "Published";
BA_ "SPNDoc" SG_ 2147483904 TransShiftSelectorDisplayModeSw "J1939-71";
BA_ "SPN" SG_ 2147483904 TransShiftSelectorDisplayModeSw 2985;
BA_ "DateSPNWasAddedModified" SG_ 2147483904 TransmissionRequestedLaunchGear "2/22/2007";
BA_ "DateSPNwasAddedToPGN" SG_ 2147483904 TransmissionRequestedLaunchGear "22-Feb-07";
BA_ "StatusOfSPNAdditionToPGN" SG_ 2147483904 TransmissionRequestedLaunchGear "Published";
BA_ "StatusOfSPN" SG_ 2147483904 TransmissionRequestedLaunchGear "Published";
BA_ "SPNDoc" SG_ 2147483904 TransmissionRequestedLaunchGear "J1939-71";
BA_ "SPN" SG_ 2147483904 TransmissionRequestedLaunchGear 4255;
BA_ "DateSPNWasAddedModified" SG_ 2147483904 TransmissionMode8 "2/21/2007";
BA_ "DateSPNwasAddedToPGN" SG_ 2147483904 TransmissionMode8 "21-Feb-07";
BA_ "StatusOfSPNAdditionToPGN" SG_ 2147483904 TransmissionMode8 "Published";
BA_ "StatusOfSPN" SG_ 2147483904 TransmissionMode8 "Published";
BA_ "SPNDoc" SG_ 2147483904 TransmissionMode8 "J1939-71";
BA_ "SPN" SG_ 2147483904 TransmissionMode8 4249;
BA_ "DateSPNWasAddedModified" SG_ 2147483904 TransmissionMode7 "2/21/2007";
BA_ "DateSPNwasAddedToPGN" SG_ 2147483904 TransmissionMode7 "21-Feb-07";
BA_ "StatusOfSPNAdditionToPGN" SG_ 2147483904 TransmissionMode7 "Published";
BA_ "StatusOfSPN" SG_ 2147483904 TransmissionMode7 "Published";
BA_ "SPNDoc" SG_ 2147483904 TransmissionMode7 "J1939-71";
BA_ "SPN" SG_ 2147483904 TransmissionMode7 4248;
BA_ "DateSPNWasAddedModified" SG_ 2147483904 TransmissionMode6 "2/21/2007";
BA_ "DateSPNwasAddedToPGN" SG_ 2147483904 TransmissionMode6 "21-Feb-07";
BA_ "StatusOfSPNAdditionToPGN" SG_ 2147483904 TransmissionMode6 "Published";
BA_ "StatusOfSPN" SG_ 2147483904 TransmissionMode6 "Published";
BA_ "SPNDoc" SG_ 2147483904 TransmissionMode6 "J1939-71";
BA_ "SPN" SG_ 2147483904 TransmissionMode6 4247;
BA_ "DateSPNWasAddedModified" SG_ 2147483904 TransmissionMode5 "2/21/2007";
BA_ "DateSPNwasAddedToPGN" SG_ 2147483904 TransmissionMode5 "21-Feb-07";
BA_ "StatusOfSPNAdditionToPGN" SG_ 2147483904 TransmissionMode5 "Published";
BA_ "StatusOfSPN" SG_ 2147483904 TransmissionMode5 "Published";
BA_ "SPNDoc" SG_ 2147483904 TransmissionMode5 "J1939-71";
BA_ "SPN" SG_ 2147483904 TransmissionMode5 4246;
BA_ "DateSPNWasAddedModified" SG_ 2147483904 TransmissionMode4 "12/31/2001";
BA_ "DateSPNwasAddedToPGN" SG_ 2147483904 TransmissionMode4 "10-Aug-00";
BA_ "StatusOfSPNAdditionToPGN" SG_ 2147483904 TransmissionMode4 "Published";
BA_ "StatusOfSPN" SG_ 2147483904 TransmissionMode4 "Published";
BA_ "SPNDoc" SG_ 2147483904 TransmissionMode4 "J1939-71";
BA_ "SPN" SG_ 2147483904 TransmissionMode4 1855;
BA_ "DateSPNWasAddedModified" SG_ 2147483904 TransmissionMode3 "12/31/2001";
BA_ "DateSPNwasAddedToPGN" SG_ 2147483904 TransmissionMode3 "10-Aug-00";
BA_ "StatusOfSPNAdditionToPGN" SG_ 2147483904 TransmissionMode3 "Published";
BA_ "StatusOfSPN" SG_ 2147483904 TransmissionMode3 "Published";
BA_ "SPNDoc" SG_ 2147483904 TransmissionMode3 "J1939-71";
BA_ "SPN" SG_ 2147483904 TransmissionMode3 1854;
BA_ "DateSPNWasAddedModified" SG_ 2147483904 TransmissionMode2 "12/31/2001";
BA_ "DateSPNwasAddedToPGN" SG_ 2147483904 TransmissionMode2 "10-Aug-00";
BA_ "StatusOfSPNAdditionToPGN" SG_ 2147483904 TransmissionMode2 "Published";
BA_ "StatusOfSPN" SG_ 2147483904 TransmissionMode2 "Published";
BA_ "SPNDoc" SG_ 2147483904 TransmissionMode2 "J1939-71";
BA_ "SPN" SG_ 2147483904 TransmissionMode2 1853;
BA_ "DateSPNWasAddedModified" SG_ 2147483904 TransmissionMode1 "12/31/2001";
BA_ "DateSPNwasAddedToPGN" SG_ 2147483904 TransmissionMode1 "10-Aug-00";
BA_ "StatusOfSPNAdditionToPGN" SG_ 2147483904 TransmissionMode1 "Published";
BA_ "StatusOfSPN" SG_ 2147483904 TransmissionMode1 "Published";
BA_ "SPNDoc" SG_ 2147483904 TransmissionMode1 "J1939-71";
BA_ "SPN" SG_ 2147483904 TransmissionMode1 1852;
BA_ "DateSPNWasAddedModified" SG_ 2147483648 EngineOverrideControlMode "11/30/2003";
BA_ "DateSPNwasAddedToPGN" SG_ 2147483648 EngineOverrideControlMode "01-Oct-98";
BA_ "StatusOfSPNAdditionToPGN" SG_ 2147483648 EngineOverrideControlMode "Published";
BA_ "StatusOfSPN" SG_ 2147483648 EngineOverrideControlMode "Published";
BA_ "SPNDoc" SG_ 2147483648 EngineOverrideControlMode "J1939-71";
BA_ "SPN" SG_ 2147483648 EngineOverrideControlMode 695;
BA_ "DateSPNWasAddedModified" SG_ 2147483648 EngRqstdSpdCtrlCond "11/30/2003";
BA_ "DateSPNwasAddedToPGN" SG_ 2147483648 EngRqstdSpdCtrlCond "01-Oct-98";
BA_ "StatusOfSPNAdditionToPGN" SG_ 2147483648 EngRqstdSpdCtrlCond "Published";
BA_ "StatusOfSPN" SG_ 2147483648 EngRqstdSpdCtrlCond "Published";
BA_ "SPNDoc" SG_ 2147483648 EngRqstdSpdCtrlCond "J1939-71";
BA_ "SPN" SG_ 2147483648 EngRqstdSpdCtrlCond 696;
BA_ "DateSPNwasAddedToPGN" SG_ 2147483648 OverrideControlModePriority "01-Oct-98";
BA_ "StatusOfSPNAdditionToPGN" SG_ 2147483648 OverrideControlModePriority "Published";
BA_ "StatusOfSPN" SG_ 2147483648 OverrideControlModePriority "Published";
BA_ "SPNDoc" SG_ 2147483648 OverrideControlModePriority "J1939-71";
BA_ "SPN" SG_ 2147483648 OverrideControlModePriority 897;
BA_ "DateSPNWasAddedModified" SG_ 2147483648 EngineRequestedSpeedSpeedLimit "11/30/2003";
BA_ "DateSPNwasAddedToPGN" SG_ 2147483648 EngineRequestedSpeedSpeedLimit "01-Oct-98";
BA_ "StatusOfSPNAdditionToPGN" SG_ 2147483648 EngineRequestedSpeedSpeedLimit "Published";
BA_ "StatusOfSPN" SG_ 2147483648 EngineRequestedSpeedSpeedLimit "Published";
BA_ "SPNDoc" SG_ 2147483648 EngineRequestedSpeedSpeedLimit "J1939-71";
BA_ "SPN" SG_ 2147483648 EngineRequestedSpeedSpeedLimit 898;
BA_ "DateSPNWasAddedModified" SG_ 2147483648 EngineRequestedTorqueTorqueLimit "11/30/2003";
BA_ "DateSPNwasAddedToPGN" SG_ 2147483648 EngineRequestedTorqueTorqueLimit "01-Oct-98";
BA_ "StatusOfSPNAdditionToPGN" SG_ 2147483648 EngineRequestedTorqueTorqueLimit "Published";
BA_ "StatusOfSPN" SG_ 2147483648 EngineRequestedTorqueTorqueLimit "Published";
BA_ "SPNDoc" SG_ 2147483648 EngineRequestedTorqueTorqueLimit "J1939-71";
BA_ "SPN" SG_ 2147483648 EngineRequestedTorqueTorqueLimit 518;
BA_ "DateSPNWasAddedModified" SG_ 2147483648 TSC1TransmissionRate "8/19/2004";
BA_ "DateSPNwasAddedToPGN" SG_ 2147483648 TSC1TransmissionRate "19-Aug-04";
BA_ "StatusOfSPNAdditionToPGN" SG_ 2147483648 TSC1TransmissionRate "Published";
BA_ "StatusOfSPN" SG_ 2147483648 TSC1TransmissionRate "Published";
BA_ "SPNDoc" SG_ 2147483648 TSC1TransmissionRate "J1939-71";
BA_ "SPN" SG_ 2147483648 TSC1TransmissionRate 3349;
BA_ "DateSPNWasAddedModified" SG_ 2147483648 TSC1ControlPurpose "8/19/2004";
BA_ "DateSPNwasAddedToPGN" SG_ 2147483648 TSC1ControlPurpose "19-Aug-04";
BA_ "StatusOfSPNAdditionToPGN" SG_ 2147483648 TSC1ControlPurpose "Published";
BA_ "StatusOfSPN" SG_ 2147483648 TSC1ControlPurpose "Published";
BA_ "SPNDoc" SG_ 2147483648 TSC1ControlPurpose "J1939-71";
BA_ "SPN" SG_ 2147483648 TSC1ControlPurpose 3350;
BA_ "DateSPNWasAddedModified" SG_ 2147483648 EngRqstdTrqHiRes "8/10/2006";
BA_ "DateSPNwasAddedToPGN" SG_ 2147483648 EngRqstdTrqHiRes "10-Aug-06";
BA_ "StatusOfSPNAdditionToPGN" SG_ 2147483648 EngRqstdTrqHiRes "Published";
BA_ "StatusOfSPN" SG_ 2147483648 EngRqstdTrqHiRes "Published";
BA_ "SPNDoc" SG_ 2147483648 EngRqstdTrqHiRes "J1939-71";
BA_ "SPN" SG_ 2147483648 EngRqstdTrqHiRes 4191;
BA_ "DateSPNWasAddedModified" SG_ 2147483648 MessageCounter "11/15/2006";
BA_ "DateSPNwasAddedToPGN" SG_ 2147483648 MessageCounter "15-Nov-06";
BA_ "StatusOfSPNAdditionToPGN" SG_ 2147483648 MessageCounter "Published";
BA_ "StatusOfSPN" SG_ 2147483648 MessageCounter "Published";
BA_ "SPNDoc" SG_ 2147483648 MessageCounter "J1939-71";
BA_ "SPN" SG_ 2147483648 MessageCounter 4206;
BA_ "DateSPNWasAddedModified" SG_ 2147483648 MessageChecksum "11/15/2006";
BA_ "DateSPNwasAddedToPGN" SG_ 2147483648 MessageChecksum "15-Nov-06";
BA_ "StatusOfSPNAdditionToPGN" SG_ 2147483648 MessageChecksum "Published";
BA_ "StatusOfSPN" SG_ 2147483648 MessageChecksum "Published";
BA_ "SPNDoc" SG_ 2147483648 MessageChecksum "J1939-71";
BA_ "SPN" SG_ 2147483648 MessageChecksum 4207;
BA_ "DateSPNWasAddedModified" SG_ 2147537664 CalibrationVerificationNumber "2/1/1999";
BA_ "DateSPNwasAddedToPGN" SG_ 2147537664 CalibrationVerificationNumber "19-May-99";
BA_ "StatusOfSPNAdditionToPGN" SG_ 2147537664 CalibrationVerificationNumber "Published";
BA_ "StatusOfSPN" SG_ 2147537664 CalibrationVerificationNumber "Published";
BA_ "SPNDoc" SG_ 2147537664 CalibrationVerificationNumber "J1939-73";
BA_ "SPN" SG_ 2147537664 CalibrationVerificationNumber 1634;
BA_ "DateSPNWasAddedModified" SG_ 2147522816 Joystick1Lamp1Command "8/15/2007";
BA_ "DateSPNwasAddedToPGN" SG_ 2147522816 Joystick1Lamp1Command "15-Aug-07";
BA_ "StatusOfSPNAdditionToPGN" SG_ 2147522816 Joystick1Lamp1Command "Approved";
BA_ "StatusOfSPN" SG_ 2147522816 Joystick1Lamp1Command "Approved";
BA_ "SPNDoc" SG_ 2147522816 Joystick1Lamp1Command "J1939-71";
BA_ "SPN" SG_ 2147522816 Joystick1Lamp1Command 4460;
BA_ "DateSPNWasAddedModified" SG_ 2147522816 Joystick1Lamp2Command "8/15/2007";
BA_ "DateSPNwasAddedToPGN" SG_ 2147522816 Joystick1Lamp2Command "15-Aug-07";
BA_ "StatusOfSPNAdditionToPGN" SG_ 2147522816 Joystick1Lamp2Command "Approved";
BA_ "StatusOfSPN" SG_ 2147522816 Joystick1Lamp2Command "Approved";
BA_ "SPNDoc" SG_ 2147522816 Joystick1Lamp2Command "J1939-71";
BA_ "SPN" SG_ 2147522816 Joystick1Lamp2Command 4461;
BA_ "DateSPNWasAddedModified" SG_ 2147522816 Joystick1Lamp3Command "8/15/2007";
BA_ "DateSPNwasAddedToPGN" SG_ 2147522816 Joystick1Lamp3Command "15-Aug-07";
BA_ "StatusOfSPNAdditionToPGN" SG_ 2147522816 Joystick1Lamp3Command "Approved";
BA_ "StatusOfSPN" SG_ 2147522816 Joystick1Lamp3Command "Approved";
BA_ "SPNDoc" SG_ 2147522816 Joystick1Lamp3Command "J1939-71";
BA_ "SPN" SG_ 2147522816 Joystick1Lamp3Command 4462;
BA_ "DateSPNWasAddedModified" SG_ 2147522816 Joystick1Lamp4Command "8/15/2007";
BA_ "DateSPNwasAddedToPGN" SG_ 2147522816 Joystick1Lamp4Command "15-Aug-07";
BA_ "StatusOfSPNAdditionToPGN" SG_ 2147522816 Joystick1Lamp4Command "Approved";
BA_ "StatusOfSPN" SG_ 2147522816 Joystick1Lamp4Command "Approved";
BA_ "SPNDoc" SG_ 2147522816 Joystick1Lamp4Command "J1939-71";
BA_ "SPN" SG_ 2147522816 Joystick1Lamp4Command 4463;
BA_ "DateSPNWasAddedModified" SG_ 2147522816 Joystick1Lamp5Command "8/15/2007";
BA_ "DateSPNwasAddedToPGN" SG_ 2147522816 Joystick1Lamp5Command "15-Aug-07";
BA_ "StatusOfSPNAdditionToPGN" SG_ 2147522816 Joystick1Lamp5Command "Approved";
BA_ "StatusOfSPN" SG_ 2147522816 Joystick1Lamp5Command "Approved";
BA_ "SPNDoc" SG_ 2147522816 Joystick1Lamp5Command "J1939-71";
BA_ "SPN" SG_ 2147522816 Joystick1Lamp5Command 4464;
BA_ "DateSPNWasAddedModified" SG_ 2147522816 Joystick1Lamp6Command "8/15/2007";
BA_ "DateSPNwasAddedToPGN" SG_ 2147522816 Joystick1Lamp6Command "15-Aug-07";
BA_ "StatusOfSPNAdditionToPGN" SG_ 2147522816 Joystick1Lamp6Command "Approved";
BA_ "StatusOfSPN" SG_ 2147522816 Joystick1Lamp6Command "Approved";
BA_ "SPNDoc" SG_ 2147522816 Joystick1Lamp6Command "J1939-71";
BA_ "SPN" SG_ 2147522816 Joystick1Lamp6Command 4465;
BA_ "DateSPNWasAddedModified" SG_ 2147522816 Joystick1Lamp7Command "8/15/2007";
BA_ "DateSPNwasAddedToPGN" SG_ 2147522816 Joystick1Lamp7Command "15-Aug-07";
BA_ "StatusOfSPNAdditionToPGN" SG_ 2147522816 Joystick1Lamp7Command "Approved";
BA_ "StatusOfSPN" SG_ 2147522816 Joystick1Lamp7Command "Approved";
BA_ "SPNDoc" SG_ 2147522816 Joystick1Lamp7Command "J1939-71";
BA_ "SPN" SG_ 2147522816 Joystick1Lamp7Command 4466;
BA_ "DateSPNWasAddedModified" SG_ 2147522816 Joystick1Lamp8Command "8/15/2007";
BA_ "DateSPNwasAddedToPGN" SG_ 2147522816 Joystick1Lamp8Command "15-Aug-07";
BA_ "StatusOfSPNAdditionToPGN" SG_ 2147522816 Joystick1Lamp8Command "Approved";
BA_ "StatusOfSPN" SG_ 2147522816 Joystick1Lamp8Command "Approved";
BA_ "SPNDoc" SG_ 2147522816 Joystick1Lamp8Command "J1939-71";
BA_ "SPN" SG_ 2147522816 Joystick1Lamp8Command 4467;
BA_ "DateSPNWasAddedModified" SG_ 2147522816 Joystick1Lamp9Command "8/15/2007";
BA_ "DateSPNwasAddedToPGN" SG_ 2147522816 Joystick1Lamp9Command "15-Aug-07";
BA_ "StatusOfSPNAdditionToPGN" SG_ 2147522816 Joystick1Lamp9Command "Approved";
BA_ "StatusOfSPN" SG_ 2147522816 Joystick1Lamp9Command "Approved";
BA_ "SPNDoc" SG_ 2147522816 Joystick1Lamp9Command "J1939-71";
BA_ "SPN" SG_ 2147522816 Joystick1Lamp9Command 4468;
BA_ "DateSPNWasAddedModified" SG_ 2147522816 Joystick1Lamp10Command "8/15/2007";
BA_ "DateSPNwasAddedToPGN" SG_ 2147522816 Joystick1Lamp10Command "15-Aug-07";
BA_ "StatusOfSPNAdditionToPGN" SG_ 2147522816 Joystick1Lamp10Command "Approved";
BA_ "StatusOfSPN" SG_ 2147522816 Joystick1Lamp10Command "Approved";
BA_ "SPNDoc" SG_ 2147522816 Joystick1Lamp10Command "J1939-71";
BA_ "SPN" SG_ 2147522816 Joystick1Lamp10Command 4469;
BA_ "DateSPNWasAddedModified" SG_ 2147522816 Joystick2Lamp1Command "8/15/2007";
BA_ "DateSPNwasAddedToPGN" SG_ 2147522816 Joystick2Lamp1Command "15-Aug-07";
BA_ "StatusOfSPNAdditionToPGN" SG_ 2147522816 Joystick2Lamp1Command "Approved";
BA_ "StatusOfSPN" SG_ 2147522816 Joystick2Lamp1Command "Approved";
BA_ "SPNDoc" SG_ 2147522816 Joystick2Lamp1Command "J1939-71";
BA_ "SPN" SG_ 2147522816 Joystick2Lamp1Command 4470;
BA_ "DateSPNWasAddedModified" SG_ 2147522816 Joystick2Lamp2Command "8/15/2007";
BA_ "DateSPNwasAddedToPGN" SG_ 2147522816 Joystick2Lamp2Command "15-Aug-07";
BA_ "StatusOfSPNAdditionToPGN" SG_ 2147522816 Joystick2Lamp2Command "Approved";
BA_ "StatusOfSPN" SG_ 2147522816 Joystick2Lamp2Command "Approved";
BA_ "SPNDoc" SG_ 2147522816 Joystick2Lamp2Command "J1939-71";
BA_ "SPN" SG_ 2147522816 Joystick2Lamp2Command 4471;
BA_ "DateSPNWasAddedModified" SG_ 2147522816 Joystick2Lamp3Command "8/15/2007";
BA_ "DateSPNwasAddedToPGN" SG_ 2147522816 Joystick2Lamp3Command "15-Aug-07";
BA_ "StatusOfSPNAdditionToPGN" SG_ 2147522816 Joystick2Lamp3Command "Approved";
BA_ "StatusOfSPN" SG_ 2147522816 Joystick2Lamp3Command "Approved";
BA_ "SPNDoc" SG_ 2147522816 Joystick2Lamp3Command "J1939-71";
BA_ "SPN" SG_ 2147522816 Joystick2Lamp3Command 4472;
BA_ "DateSPNWasAddedModified" SG_ 2147522816 Joystick2Lamp4Command "8/15/2007";
BA_ "DateSPNwasAddedToPGN" SG_ 2147522816 Joystick2Lamp4Command "15-Aug-07";
BA_ "StatusOfSPNAdditionToPGN" SG_ 2147522816 Joystick2Lamp4Command "Approved";
BA_ "StatusOfSPN" SG_ 2147522816 Joystick2Lamp4Command "Approved";
BA_ "SPNDoc" SG_ 2147522816 Joystick2Lamp4Command "J1939-71";
BA_ "SPN" SG_ 2147522816 Joystick2Lamp4Command 4473;
BA_ "DateSPNWasAddedModified" SG_ 2147522816 Joystick2Lamp5Command "8/15/2007";
BA_ "DateSPNwasAddedToPGN" SG_ 2147522816 Joystick2Lamp5Command "15-Aug-07";
BA_ "StatusOfSPNAdditionToPGN" SG_ 2147522816 Joystick2Lamp5Command "Approved";
BA_ "StatusOfSPN" SG_ 2147522816 Joystick2Lamp5Command "Approved";
BA_ "SPNDoc" SG_ 2147522816 Joystick2Lamp5Command "J1939-71";
BA_ "SPN" SG_ 2147522816 Joystick2Lamp5Command 4474;
BA_ "DateSPNWasAddedModified" SG_ 2147522816 Joystick2Lamp6Command "8/15/2007";
BA_ "DateSPNwasAddedToPGN" SG_ 2147522816 Joystick2Lamp6Command "15-Aug-07";
BA_ "StatusOfSPNAdditionToPGN" SG_ 2147522816 Joystick2Lamp6Command "Approved";
BA_ "StatusOfSPN" SG_ 2147522816 Joystick2Lamp6Command "Approved";
BA_ "SPNDoc" SG_ 2147522816 Joystick2Lamp6Command "J1939-71";
BA_ "SPN" SG_ 2147522816 Joystick2Lamp6Command 4475;
BA_ "DateSPNWasAddedModified" SG_ 2147522816 Joystick2Lamp7Command "8/15/2007";
BA_ "DateSPNwasAddedToPGN" SG_ 2147522816 Joystick2Lamp7Command "15-Aug-07";
BA_ "StatusOfSPNAdditionToPGN" SG_ 2147522816 Joystick2Lamp7Command "Approved";
BA_ "StatusOfSPN" SG_ 2147522816 Joystick2Lamp7Command "Approved";
BA_ "SPNDoc" SG_ 2147522816 Joystick2Lamp7Command "J1939-71";
BA_ "SPN" SG_ 2147522816 Joystick2Lamp7Command 4476;
BA_ "DateSPNWasAddedModified" SG_ 2147522816 Joystick2Lamp8Command "8/15/2007";
BA_ "DateSPNwasAddedToPGN" SG_ 2147522816 Joystick2Lamp8Command "15-Aug-07";
BA_ "StatusOfSPNAdditionToPGN" SG_ 2147522816 Joystick2Lamp8Command "Approved";
BA_ "StatusOfSPN" SG_ 2147522816 Joystick2Lamp8Command "Approved";
BA_ "SPNDoc" SG_ 2147522816 Joystick2Lamp8Command "J1939-71";
BA_ "SPN" SG_ 2147522816 Joystick2Lamp8Command 4477;
BA_ "DateSPNWasAddedModified" SG_ 2147522816 Joystick2Lamp9Command "8/15/2007";
BA_ "DateSPNwasAddedToPGN" SG_ 2147522816 Joystick2Lamp9Command "15-Aug-07";
BA_ "StatusOfSPNAdditionToPGN" SG_ 2147522816 Joystick2Lamp9Command "Approved";
BA_ "StatusOfSPN" SG_ 2147522816 Joystick2Lamp9Command "Approved";
BA_ "SPNDoc" SG_ 2147522816 Joystick2Lamp9Command "J1939-71";
BA_ "SPN" SG_ 2147522816 Joystick2Lamp9Command 4478;
BA_ "DateSPNWasAddedModified" SG_ 2147522816 Joystick2Lamp10Command "8/15/2007";
BA_ "DateSPNwasAddedToPGN" SG_ 2147522816 Joystick2Lamp10Command "15-Aug-07";
BA_ "StatusOfSPNAdditionToPGN" SG_ 2147522816 Joystick2Lamp10Command "Approved";
BA_ "StatusOfSPN" SG_ 2147522816 Joystick2Lamp10Command "Approved";
BA_ "SPNDoc" SG_ 2147522816 Joystick2Lamp10Command "J1939-71";
BA_ "SPN" SG_ 2147522816 Joystick2Lamp10Command 4479;
BA_ "DateSPNWasAddedModified" SG_ 2147522816 Joystick3Lamp1Command "8/15/2007";
BA_ "DateSPNwasAddedToPGN" SG_ 2147522816 Joystick3Lamp1Command "15-Aug-07";
BA_ "StatusOfSPNAdditionToPGN" SG_ 2147522816 Joystick3Lamp1Command "Approved";
BA_ "StatusOfSPN" SG_ 2147522816 Joystick3Lamp1Command "Approved";
BA_ "SPNDoc" SG_ 2147522816 Joystick3Lamp1Command "J1939-71";
BA_ "SPN" SG_ 2147522816 Joystick3Lamp1Command 4480;
BA_ "DateSPNWasAddedModified" SG_ 2147522816 Joystick3Lamp2Command "8/15/2007";
BA_ "DateSPNwasAddedToPGN" SG_ 2147522816 Joystick3Lamp2Command "15-Aug-07";
BA_ "StatusOfSPNAdditionToPGN" SG_ 2147522816 Joystick3Lamp2Command "Approved";
BA_ "StatusOfSPN" SG_ 2147522816 Joystick3Lamp2Command "Approved";
BA_ "SPNDoc" SG_ 2147522816 Joystick3Lamp2Command "J1939-71";
BA_ "SPN" SG_ 2147522816 Joystick3Lamp2Command 4481;
BA_ "DateSPNWasAddedModified" SG_ 2147522816 Joystick3Lamp3Command "8/15/2007";
BA_ "DateSPNwasAddedToPGN" SG_ 2147522816 Joystick3Lamp3Command "15-Aug-07";
BA_ "StatusOfSPNAdditionToPGN" SG_ 2147522816 Joystick3Lamp3Command "Approved";
BA_ "StatusOfSPN" SG_ 2147522816 Joystick3Lamp3Command "Approved";
BA_ "SPNDoc" SG_ 2147522816 Joystick3Lamp3Command "J1939-71";
BA_ "SPN" SG_ 2147522816 Joystick3Lamp3Command 4482;
BA_ "DateSPNWasAddedModified" SG_ 2147522816 Joystick3Lamp4Command "8/15/2007";
BA_ "DateSPNwasAddedToPGN" SG_ 2147522816 Joystick3Lamp4Command "15-Aug-07";
BA_ "StatusOfSPNAdditionToPGN" SG_ 2147522816 Joystick3Lamp4Command "Approved";
BA_ "StatusOfSPN" SG_ 2147522816 Joystick3Lamp4Command "Approved";
BA_ "SPNDoc" SG_ 2147522816 Joystick3Lamp4Command "J1939-71";
BA_ "SPN" SG_ 2147522816 Joystick3Lamp4Command 4483;
BA_ "DateSPNWasAddedModified" SG_ 2147522816 Joystick3Lamp5Command "8/15/2007";
BA_ "DateSPNwasAddedToPGN" SG_ 2147522816 Joystick3Lamp5Command "15-Aug-07";
BA_ "StatusOfSPNAdditionToPGN" SG_ 2147522816 Joystick3Lamp5Command "Approved";
BA_ "StatusOfSPN" SG_ 2147522816 Joystick3Lamp5Command "Approved";
BA_ "SPNDoc" SG_ 2147522816 Joystick3Lamp5Command "J1939-71";
BA_ "SPN" SG_ 2147522816 Joystick3Lamp5Command 4484;
BA_ "DateSPNWasAddedModified" SG_ 2147522816 Joystick3Lamp6Command "8/15/2007";
BA_ "DateSPNwasAddedToPGN" SG_ 2147522816 Joystick3Lamp6Command "15-Aug-07";
BA_ "StatusOfSPNAdditionToPGN" SG_ 2147522816 Joystick3Lamp6Command "Approved";
BA_ "StatusOfSPN" SG_ 2147522816 Joystick3Lamp6Command "Approved";
BA_ "SPNDoc" SG_ 2147522816 Joystick3Lamp6Command "J1939-71";
BA_ "SPN" SG_ 2147522816 Joystick3Lamp6Command 4485;
BA_ "DateSPNWasAddedModified" SG_ 2147522816 Joystick3Lamp7Command "8/15/2007";
BA_ "DateSPNwasAddedToPGN" SG_ 2147522816 Joystick3Lamp7Command "15-Aug-07";
BA_ "StatusOfSPNAdditionToPGN" SG_ 2147522816 Joystick3Lamp7Command "Approved";
BA_ "StatusOfSPN" SG_ 2147522816 Joystick3Lamp7Command "Approved";
BA_ "SPNDoc" SG_ 2147522816 Joystick3Lamp7Command "J1939-71";
BA_ "SPN" SG_ 2147522816 Joystick3Lamp7Command 4486;
BA_ "DateSPNWasAddedModified" SG_ 2147522816 Joystick3Lamp8Command "8/15/2007";
BA_ "DateSPNwasAddedToPGN" SG_ 2147522816 Joystick3Lamp8Command "15-Aug-07";
BA_ "StatusOfSPNAdditionToPGN" SG_ 2147522816 Joystick3Lamp8Command "Approved";
BA_ "StatusOfSPN" SG_ 2147522816 Joystick3Lamp8Command "Approved";
BA_ "SPNDoc" SG_ 2147522816 Joystick3Lamp8Command "J1939-71";
BA_ "SPN" SG_ 2147522816 Joystick3Lamp8Command 4487;
BA_ "DateSPNWasAddedModified" SG_ 2147522816 Joystick3Lamp9Command "8/15/2007";
BA_ "DateSPNwasAddedToPGN" SG_ 2147522816 Joystick3Lamp9Command "15-Aug-07";
BA_ "StatusOfSPNAdditionToPGN" SG_ 2147522816 Joystick3Lamp9Command "Approved";
BA_ "StatusOfSPN" SG_ 2147522816 Joystick3Lamp9Command "Approved";
BA_ "SPNDoc" SG_ 2147522816 Joystick3Lamp9Command "J1939-71";
BA_ "SPN" SG_ 2147522816 Joystick3Lamp9Command 4488;
BA_ "DateSPNWasAddedModified" SG_ 2147522816 Joystick3Lamp10Command "8/15/2007";
BA_ "DateSPNwasAddedToPGN" SG_ 2147522816 Joystick3Lamp10Command "15-Aug-07";
BA_ "StatusOfSPNAdditionToPGN" SG_ 2147522816 Joystick3Lamp10Command "Approved";
BA_ "StatusOfSPN" SG_ 2147522816 Joystick3Lamp10Command "Approved";
BA_ "SPNDoc" SG_ 2147522816 Joystick3Lamp10Command "J1939-71";
BA_ "SPN" SG_ 2147522816 Joystick3Lamp10Command 4489;
BA_ "DateSPNWasAddedModified" SG_ 2147548747 TransmissionTorqueLimit "12/31/2001";
BA_ "DateSPNwasAddedToPGN" SG_ 2147548747 TransmissionTorqueLimit "09-Nov-00";
BA_ "StatusOfSPNAdditionToPGN" SG_ 2147548747 TransmissionTorqueLimit "Published";
BA_ "StatusOfSPN" SG_ 2147548747 TransmissionTorqueLimit "Published";
BA_ "SPNDoc" SG_ 2147548747 TransmissionTorqueLimit "J1939-71";
BA_ "SPN" SG_ 2147548747 TransmissionTorqueLimit 1845;
BA_ "DateSPNwasAddedToPGN" SG_ 2147548899 EngineSpeedAtIdlePoint1 "01-Oct-98";
BA_ "StatusOfSPNAdditionToPGN" SG_ 2147548899 EngineSpeedAtIdlePoint1 "Published";
BA_ "StatusOfSPN" SG_ 2147548899 EngineSpeedAtIdlePoint1 "Published";
BA_ "SPNDoc" SG_ 2147548899 EngineSpeedAtIdlePoint1 "J1939-71";
BA_ "SPN" SG_ 2147548899 EngineSpeedAtIdlePoint1 188;
BA_ "DateSPNWasAddedModified" SG_ 2147548899 EnginePercentTorqueAtIdlePoint1 "11/30/2003";
BA_ "DateSPNwasAddedToPGN" SG_ 2147548899 EnginePercentTorqueAtIdlePoint1 "01-Oct-98";
BA_ "StatusOfSPNAdditionToPGN" SG_ 2147548899 EnginePercentTorqueAtIdlePoint1 "Published";
BA_ "StatusOfSPN" SG_ 2147548899 EnginePercentTorqueAtIdlePoint1 "Published";
BA_ "SPNDoc" SG_ 2147548899 EnginePercentTorqueAtIdlePoint1 "J1939-71";
BA_ "SPN" SG_ 2147548899 EnginePercentTorqueAtIdlePoint1 539;
BA_ "DateSPNwasAddedToPGN" SG_ 2147548899 EngineSpeedAtPoint2 "01-Oct-98";
BA_ "StatusOfSPNAdditionToPGN" SG_ 2147548899 EngineSpeedAtPoint2 "Published";
BA_ "StatusOfSPN" SG_ 2147548899 EngineSpeedAtPoint2 "Published";
BA_ "SPNDoc" SG_ 2147548899 EngineSpeedAtPoint2 "J1939-71";
BA_ "SPN" SG_ 2147548899 EngineSpeedAtPoint2 528;
BA_ "DateSPNWasAddedModified" SG_ 2147548899 EnginePercentTorqueAtPoint2 "11/30/2003";
BA_ "DateSPNwasAddedToPGN" SG_ 2147548899 EnginePercentTorqueAtPoint2 "01-Oct-98";
BA_ "StatusOfSPNAdditionToPGN" SG_ 2147548899 EnginePercentTorqueAtPoint2 "Published";
BA_ "StatusOfSPN" SG_ 2147548899 EnginePercentTorqueAtPoint2 "Published";
BA_ "SPNDoc" SG_ 2147548899 EnginePercentTorqueAtPoint2 "J1939-71";
BA_ "SPN" SG_ 2147548899 EnginePercentTorqueAtPoint2 540;
BA_ "DateSPNwasAddedToPGN" SG_ 2147548899 EngineSpeedAtPoint3 "01-Oct-98";
BA_ "StatusOfSPNAdditionToPGN" SG_ 2147548899 EngineSpeedAtPoint3 "Published";
BA_ "StatusOfSPN" SG_ 2147548899 EngineSpeedAtPoint3 "Published";
BA_ "SPNDoc" SG_ 2147548899 EngineSpeedAtPoint3 "J1939-71";
BA_ "SPN" SG_ 2147548899 EngineSpeedAtPoint3 529;
BA_ "DateSPNWasAddedModified" SG_ 2147548899 EnginePercentTorqueAtPoint3 "11/30/2003";
BA_ "DateSPNwasAddedToPGN" SG_ 2147548899 EnginePercentTorqueAtPoint3 "01-Oct-98";
BA_ "StatusOfSPNAdditionToPGN" SG_ 2147548899 EnginePercentTorqueAtPoint3 "Published";
BA_ "StatusOfSPN" SG_ 2147548899 EnginePercentTorqueAtPoint3 "Published";
BA_ "SPNDoc" SG_ 2147548899 EnginePercentTorqueAtPoint3 "J1939-71";
BA_ "SPN" SG_ 2147548899 EnginePercentTorqueAtPoint3 541;
BA_ "DateSPNwasAddedToPGN" SG_ 2147548899 EngineSpeedAtPoint4 "01-Oct-98";
BA_ "StatusOfSPNAdditionToPGN" SG_ 2147548899 EngineSpeedAtPoint4 "Published";
BA_ "StatusOfSPN" SG_ 2147548899 EngineSpeedAtPoint4 "Published";
BA_ "SPNDoc" SG_ 2147548899 EngineSpeedAtPoint4 "J1939-71";
BA_ "SPN" SG_ 2147548899 EngineSpeedAtPoint4 530;
BA_ "DateSPNWasAddedModified" SG_ 2147548899 EnginePercentTorqueAtPoint4 "11/30/2003";
BA_ "DateSPNwasAddedToPGN" SG_ 2147548899 EnginePercentTorqueAtPoint4 "01-Oct-98";
BA_ "StatusOfSPNAdditionToPGN" SG_ 2147548899 EnginePercentTorqueAtPoint4 "Published";
BA_ "StatusOfSPN" SG_ 2147548899 EnginePercentTorqueAtPoint4 "Published";
BA_ "SPNDoc" SG_ 2147548899 EnginePercentTorqueAtPoint4 "J1939-71";
BA_ "SPN" SG_ 2147548899 EnginePercentTorqueAtPoint4 542;
BA_ "DateSPNwasAddedToPGN" SG_ 2147548899 EngineSpeedAtPoint5 "01-Oct-98";
BA_ "StatusOfSPNAdditionToPGN" SG_ 2147548899 EngineSpeedAtPoint5 "Published";
BA_ "StatusOfSPN" SG_ 2147548899 EngineSpeedAtPoint5 "Published";
BA_ "SPNDoc" SG_ 2147548899 EngineSpeedAtPoint5 "J1939-71";
BA_ "SPN" SG_ 2147548899 EngineSpeedAtPoint5 531;
BA_ "DateSPNWasAddedModified" SG_ 2147548899 EnginePercentTorqueAtPoint5 "11/30/2003";
BA_ "DateSPNwasAddedToPGN" SG_ 2147548899 EnginePercentTorqueAtPoint5 "01-Oct-98";
BA_ "StatusOfSPNAdditionToPGN" SG_ 2147548899 EnginePercentTorqueAtPoint5 "Published";
BA_ "StatusOfSPN" SG_ 2147548899 EnginePercentTorqueAtPoint5 "Published";
BA_ "SPNDoc" SG_ 2147548899 EnginePercentTorqueAtPoint5 "J1939-71";
BA_ "SPN" SG_ 2147548899 EnginePercentTorqueAtPoint5 543;
BA_ "DateSPNWasAddedModified" SG_ 2147548899 EngineSpeedAtHighIdlePoint6 "11/30/2003";
BA_ "DateSPNwasAddedToPGN" SG_ 2147548899 EngineSpeedAtHighIdlePoint6 "01-Oct-98";
BA_ "StatusOfSPNAdditionToPGN" SG_ 2147548899 EngineSpeedAtHighIdlePoint6 "Published";
BA_ "StatusOfSPN" SG_ 2147548899 EngineSpeedAtHighIdlePoint6 "Published";
BA_ "SPNDoc" SG_ 2147548899 EngineSpeedAtHighIdlePoint6 "J1939-71";
BA_ "SPN" SG_ 2147548899 EngineSpeedAtHighIdlePoint6 532;
BA_ "DateSPNWasAddedModified" SG_ 2147548899 EngineGain "11/30/2003";
BA_ "DateSPNwasAddedToPGN" SG_ 2147548899 EngineGain "01-Oct-98";
BA_ "StatusOfSPNAdditionToPGN" SG_ 2147548899 EngineGain "Published";
BA_ "StatusOfSPN" SG_ 2147548899 EngineGain "Published";
BA_ "SPNDoc" SG_ 2147548899 EngineGain "J1939-71";
BA_ "SPN" SG_ 2147548899 EngineGain 545;
BA_ "DateSPNWasAddedModified" SG_ 2147548899 EngineReferenceTorque "12/25/2003";
BA_ "DateSPNwasAddedToPGN" SG_ 2147548899 EngineReferenceTorque "01-Oct-98";
BA_ "StatusOfSPNAdditionToPGN" SG_ 2147548899 EngineReferenceTorque "Published";
BA_ "StatusOfSPN" SG_ 2147548899 EngineReferenceTorque "Published";
BA_ "SPNDoc" SG_ 2147548899 EngineReferenceTorque "J1939-71";
BA_ "SPN" SG_ 2147548899 EngineReferenceTorque 544;
BA_ "DateSPNWasAddedModified" SG_ 2147548899 EngMaxMomentaryOverrideSpdPoint7 "12/25/2003";
BA_ "DateSPNwasAddedToPGN" SG_ 2147548899 EngMaxMomentaryOverrideSpdPoint7 "01-Oct-98";
BA_ "StatusOfSPNAdditionToPGN" SG_ 2147548899 EngMaxMomentaryOverrideSpdPoint7 "Published";
BA_ "StatusOfSPN" SG_ 2147548899 EngMaxMomentaryOverrideSpdPoint7 "Published";
BA_ "SPNDoc" SG_ 2147548899 EngMaxMomentaryOverrideSpdPoint7 "J1939-71";
BA_ "SPN" SG_ 2147548899 EngMaxMomentaryOverrideSpdPoint7 533;
BA_ "DateSPNWasAddedModified" SG_ 2147548899 EngMaxMomentaryOverrideTimeLmt "11/30/2003";
BA_ "DateSPNwasAddedToPGN" SG_ 2147548899 EngMaxMomentaryOverrideTimeLmt "01-Oct-98";
BA_ "StatusOfSPNAdditionToPGN" SG_ 2147548899 EngMaxMomentaryOverrideTimeLmt "Published";
BA_ "StatusOfSPN" SG_ 2147548899 EngMaxMomentaryOverrideTimeLmt "Published";
BA_ "SPNDoc" SG_ 2147548899 EngMaxMomentaryOverrideTimeLmt "J1939-71";
BA_ "SPN" SG_ 2147548899 EngMaxMomentaryOverrideTimeLmt 534;
BA_ "DateSPNWasAddedModified" SG_ 2147548899 EngRqstdSpdCtrlRngLowerLmt "11/30/2003";
BA_ "DateSPNwasAddedToPGN" SG_ 2147548899 EngRqstdSpdCtrlRngLowerLmt "01-Oct-98";
BA_ "StatusOfSPNAdditionToPGN" SG_ 2147548899 EngRqstdSpdCtrlRngLowerLmt "Published";
BA_ "StatusOfSPN" SG_ 2147548899 EngRqstdSpdCtrlRngLowerLmt "Published";
BA_ "SPNDoc" SG_ 2147548899 EngRqstdSpdCtrlRngLowerLmt "J1939-71";
BA_ "SPN" SG_ 2147548899 EngRqstdSpdCtrlRngLowerLmt 535;
BA_ "DateSPNWasAddedModified" SG_ 2147548899 EngRqstdSpdCtrlRngUpperLmt "11/30/2003";
BA_ "DateSPNwasAddedToPGN" SG_ 2147548899 EngRqstdSpdCtrlRngUpperLmt "02-Aug-01";
BA_ "StatusOfSPNAdditionToPGN" SG_ 2147548899 EngRqstdSpdCtrlRngUpperLmt "Published";
BA_ "StatusOfSPN" SG_ 2147548899 EngRqstdSpdCtrlRngUpperLmt "Published";
BA_ "SPNDoc" SG_ 2147548899 EngRqstdSpdCtrlRngUpperLmt "J1939-71";
BA_ "SPN" SG_ 2147548899 EngRqstdSpdCtrlRngUpperLmt 536;
BA_ "DateSPNWasAddedModified" SG_ 2147548899 EngRqstdTrqCtrlRngLowerLmt "11/30/2003";
BA_ "DateSPNwasAddedToPGN" SG_ 2147548899 EngRqstdTrqCtrlRngLowerLmt "01-Oct-98";
BA_ "StatusOfSPNAdditionToPGN" SG_ 2147548899 EngRqstdTrqCtrlRngLowerLmt "Published";
BA_ "StatusOfSPN" SG_ 2147548899 EngRqstdTrqCtrlRngLowerLmt "Published";
BA_ "SPNDoc" SG_ 2147548899 EngRqstdTrqCtrlRngLowerLmt "J1939-71";
BA_ "SPN" SG_ 2147548899 EngRqstdTrqCtrlRngLowerLmt 537;
BA_ "DateSPNWasAddedModified" SG_ 2147548899 EngRqstdTrqCtrlRngUpperLmt "11/30/2003";
BA_ "DateSPNwasAddedToPGN" SG_ 2147548899 EngRqstdTrqCtrlRngUpperLmt "01-Oct-98";
BA_ "StatusOfSPNAdditionToPGN" SG_ 2147548899 EngRqstdTrqCtrlRngUpperLmt "Published";
BA_ "StatusOfSPN" SG_ 2147548899 EngRqstdTrqCtrlRngUpperLmt "Published";
BA_ "SPNDoc" SG_ 2147548899 EngRqstdTrqCtrlRngUpperLmt "J1939-71";
BA_ "SPN" SG_ 2147548899 EngRqstdTrqCtrlRngUpperLmt 538;
BA_ "DateSPNWasAddedModified" SG_ 2147548899 EngineMomentOfInertia "12/31/2001";
BA_ "DateSPNwasAddedToPGN" SG_ 2147548899 EngineMomentOfInertia "10-Feb-00";
BA_ "StatusOfSPNAdditionToPGN" SG_ 2147548899 EngineMomentOfInertia "Published";
BA_ "StatusOfSPN" SG_ 2147548899 EngineMomentOfInertia "Published";
BA_ "SPNDoc" SG_ 2147548899 EngineMomentOfInertia "J1939-71";
BA_ "SPN" SG_ 2147548899 EngineMomentOfInertia 1794;
BA_ "DateSPNWasAddedModified" SG_ 2147548899 EngineDefaultTorqueLimit "11/30/2003";
BA_ "DateSPNwasAddedToPGN" SG_ 2147548899 EngineDefaultTorqueLimit "10-Aug-00";
BA_ "StatusOfSPNAdditionToPGN" SG_ 2147548899 EngineDefaultTorqueLimit "Published";
BA_ "StatusOfSPN" SG_ 2147548899 EngineDefaultTorqueLimit "Published";
BA_ "SPNDoc" SG_ 2147548899 EngineDefaultTorqueLimit "J1939-71";
BA_ "SPN" SG_ 2147548899 EngineDefaultTorqueLimit 1846;
BA_ "DateSPNWasAddedModified" SG_ 2147548899 SupportVariableRateTSC1Message "8/18/2004";
BA_ "DateSPNwasAddedToPGN" SG_ 2147548899 SupportVariableRateTSC1Message "19-Aug-04";
BA_ "StatusOfSPNAdditionToPGN" SG_ 2147548899 SupportVariableRateTSC1Message "Published";
BA_ "StatusOfSPN" SG_ 2147548899 SupportVariableRateTSC1Message "Published";
BA_ "SPNDoc" SG_ 2147548899 SupportVariableRateTSC1Message "J1939-71";
BA_ "SPN" SG_ 2147548899 SupportVariableRateTSC1Message 3344;
BA_ "DateSPNWasAddedModified" SG_ 2147548899 SupportTSC1ControlPurposeGroup1 "8/19/2004";
BA_ "DateSPNwasAddedToPGN" SG_ 2147548899 SupportTSC1ControlPurposeGroup1 "19-Aug-04";
BA_ "StatusOfSPNAdditionToPGN" SG_ 2147548899 SupportTSC1ControlPurposeGroup1 "Published";
BA_ "StatusOfSPN" SG_ 2147548899 SupportTSC1ControlPurposeGroup1 "Published";
BA_ "SPNDoc" SG_ 2147548899 SupportTSC1ControlPurposeGroup1 "J1939-71";
BA_ "SPN" SG_ 2147548899 SupportTSC1ControlPurposeGroup1 3345;
BA_ "DateSPNWasAddedModified" SG_ 2147548899 SupportTSC1ControlPurposeGroup2 "8/19/2004";
BA_ "DateSPNwasAddedToPGN" SG_ 2147548899 SupportTSC1ControlPurposeGroup2 "19-Aug-04";
BA_ "StatusOfSPNAdditionToPGN" SG_ 2147548899 SupportTSC1ControlPurposeGroup2 "Published";
BA_ "StatusOfSPN" SG_ 2147548899 SupportTSC1ControlPurposeGroup2 "Published";
BA_ "SPNDoc" SG_ 2147548899 SupportTSC1ControlPurposeGroup2 "J1939-71";
BA_ "SPN" SG_ 2147548899 SupportTSC1ControlPurposeGroup2 3346;
BA_ "DateSPNWasAddedModified" SG_ 2147548899 SupportTSC1ControlPurposeGroup3 "8/19/2004";
BA_ "DateSPNwasAddedToPGN" SG_ 2147548899 SupportTSC1ControlPurposeGroup3 "19-Aug-04";
BA_ "StatusOfSPNAdditionToPGN" SG_ 2147548899 SupportTSC1ControlPurposeGroup3 "Published";
BA_ "StatusOfSPN" SG_ 2147548899 SupportTSC1ControlPurposeGroup3 "Published";
BA_ "SPNDoc" SG_ 2147548899 SupportTSC1ControlPurposeGroup3 "J1939-71";
BA_ "SPN" SG_ 2147548899 SupportTSC1ControlPurposeGroup3 3347;
BA_ "DateSPNWasAddedModified" SG_ 2147548899 SupportTSC1ControlPurposeGroup4 "8/19/2004";
BA_ "DateSPNwasAddedToPGN" SG_ 2147548899 SupportTSC1ControlPurposeGroup4 "19-Aug-04";
BA_ "StatusOfSPNAdditionToPGN" SG_ 2147548899 SupportTSC1ControlPurposeGroup4 "Published";
BA_ "StatusOfSPN" SG_ 2147548899 SupportTSC1ControlPurposeGroup4 "Published";
BA_ "SPNDoc" SG_ 2147548899 SupportTSC1ControlPurposeGroup4 "J1939-71";
BA_ "SPN" SG_ 2147548899 SupportTSC1ControlPurposeGroup4 3348;
VAL_ 2147483904 DisengageDiffrlLockRqstRearAxle2 3 "Take no action" 2 "Reserved" 1 "Disengage differential lock" 0 "Engage differential lock" ;
VAL_ 2147483904 DisengageDiffrlLockRqstRearAxle1 3 "Take no action" 2 "Reserved" 1 "Disengage differential lock" 0 "Engage differential lock" ;
VAL_ 2147483904 DisengageDiffrlLockRqstFntAxle2 3 "Take no action" 2 "Reserved" 1 "Disengage differential lock" 0 "Engage differential lock" ;
VAL_ 2147483904 DisengageDiffrlLockRqstFntAxle1 3 "Take no action" 2 "Reserved" 1 "Disengage differential lock" 0 "Engage differential lock" ;
VAL_ 2147483904 DisengageDiffrlLockRqstCentrRear 3 "Take no action" 2 "Reserved" 1 "Disengage differential lock" 0 "Engage differential lock" ;
VAL_ 2147483904 DisengageDiffrlLockRqstCentrFnt 3 "Take no action" 2 "Reserved" 1 "Disengage differential lock" 0 "Engage differential lock" ;
VAL_ 2147483904 DisengageDiffrlLockRqstCentr 3 "Take no action" 2 "Reserved" 1 "Disengage differential lock" 0 "Engage differential lock" ;
VAL_ 2147483904 DisengageDrivelineRequest 3 "Take no action" 2 "Reserved" 1 "Disengage driveline" 0 "Allow driveline engagement" ;
VAL_ 2147483904 TransTrqCvtrLockupDisableRqst 3 "Take no action" 2 "Reserved" 1 "Disable torque converter lockup" 0 "Allow torque converter lockup" ;
VAL_ 2147483904 TransGearShiftInhibitRqst 3 "Take no action" 2 "Reserved" 1 "Gear shifts are inhibited" 0 "Gear shifts are allowed" ;
VAL_ 2147483904 TransmissionRequestedLaunchGear 15 "Not Available" 14 "Error" 13 "Reserved" 12 "Launch the vehicle in Reverse 4" 11 "Launch the vehicle in Reverse 3" 10 "Launch the vehicle in Reverse 2" 9 "Launch the vehicle in Reverse 1" 8 "Launch the vehicle in 8th gear" 7 "Launch the vehicle in 7th gear" 6 "Launch the vehicle in 6th gear" 5 "Launch the vehicle in 5th gear" 4 "Launch the vehicle in 4th gear" 3 "Launch the vehicle in 3rd gear" 2 "Launch the vehicle in 2nd gear" 1 "Launch the vehicle in 1st gear" 0 "No specific launch gear requested; use default launch gear" ;
VAL_ 2147483904 TransmissionMode8 3 "Take no action" 2 "Reserved" 1 "Enable" 0 "Disable" ;
VAL_ 2147483904 TransmissionMode7 3 "Take no action" 2 "Reserved" 1 "Enable" 0 "Disable" ;
VAL_ 2147483904 TransmissionMode6 3 "Take no action" 2 "Reserved" 1 "Enable" 0 "Disable" ;
VAL_ 2147483904 TransmissionMode5 3 "Take no action" 2 "Reserved" 1 "Enable" 0 "Disable" ;
VAL_ 2147483904 TransmissionMode4 3 "Take no action" 2 "Reserved" 1 "Enable" 0 "Disable" ;
VAL_ 2147483904 TransmissionMode3 3 "Take no action" 2 "Reserved" 1 "Enable" 0 "Disable" ;
VAL_ 2147483904 TransmissionMode2 3 "Take no action" 2 "Reserved" 1 "Enable" 0 "Disable" ;
VAL_ 2147483904 TransmissionMode1 3 "Take no action" 2 "Reserved" 1 "Enable" 0 "Disable" ;
VAL_ 2147483648 EngineOverrideControlMode 3 "Speed/torque limit control" 2 "Torque control" 1 "Speed control" 0 "Override disabled" ;
VAL_ 2147483648 EngRqstdSpdCtrlCond 3 "Stability Optimized for driveline engaged and/or in lockup condition 2" 2 "Stability Optimized for driveline engaged and/or in lockup condition 1" 1 "Stability Optimized for driveline disengaged and non-lockup conditions" 0 "Transient Optimized for driveline disengaged and non-lockup conditions" ;
VAL_ 2147522816 Joystick1Lamp1Command 3 "Not available or not installed" 2 "Blinking" 1 "On" 0 "Off" ;
VAL_ 2147522816 Joystick1Lamp2Command 3 "Not available or not installed" 2 "Blinking" 1 "On" 0 "Off" ;
VAL_ 2147522816 Joystick1Lamp3Command 3 "Not available or not installed" 2 "Blinking" 1 "On" 0 "Off" ;
VAL_ 2147522816 Joystick1Lamp4Command 3 "Not available or not installed" 2 "Blinking" 1 "On" 0 "Off" ;
VAL_ 2147522816 Joystick1Lamp5Command 3 "Not available or not installed" 2 "Blinking" 1 "On" 0 "Off" ;
VAL_ 2147522816 Joystick1Lamp6Command 3 "Not available or not installed" 2 "Blinking" 1 "On" 0 "Off" ;
VAL_ 2147522816 Joystick1Lamp7Command 3 "Not available or not installed" 2 "Blinking" 1 "On" 0 "Off" ;
VAL_ 2147522816 Joystick1Lamp8Command 3 "Not available or not installed" 2 "Blinking" 1 "On" 0 "Off" ;
VAL_ 2147522816 Joystick1Lamp9Command 3 "Not available or not installed" 2 "Blinking" 1 "On" 0 "Off" ;
VAL_ 2147522816 Joystick1Lamp10Command 3 "Not available or not installed" 2 "Blinking" 1 "On" 0 "Off" ;
VAL_ 2147522816 Joystick2Lamp1Command 3 "Not available or not installed" 2 "Blinking" 1 "On" 0 "Off" ;
VAL_ 2147522816 Joystick2Lamp2Command 3 "Not available or not installed" 2 "Blinking" 1 "On" 0 "Off" ;
VAL_ 2147522816 Joystick2Lamp3Command 3 "Not available or not installed" 2 "Blinking" 1 "On" 0 "Off" ;
VAL_ 2147522816 Joystick2Lamp4Command 3 "Not available or not installed" 2 "Blinking" 1 "On" 0 "Off" ;
VAL_ 2147522816 Joystick2Lamp5Command 3 "Not available or not installed" 2 "Blinking" 1 "On" 0 "Off" ;
VAL_ 2147522816 Joystick2Lamp6Command 3 "Not available or not installed" 2 "Blinking" 1 "On" 0 "Off" ;
VAL_ 2147522816 Joystick2Lamp7Command 3 "Not available or not installed" 2 "Blinking" 1 "On" 0 "Off" ;
VAL_ 2147522816 Joystick2Lamp8Command 3 "Not available or not installed" 2 "Blinking" 1 "On" 0 "Off" ;
VAL_ 2147522816 Joystick2Lamp9Command 3 "Not available or not installed" 2 "Blinking" 1 "On" 0 "Off" ;
VAL_ 2147522816 Joystick2Lamp10Command 3 "Not available or not installed" 2 "Blinking" 1 "On" 0 "Off" ;
VAL_ 2147522816 Joystick3Lamp1Command 3 "Not available or not installed" 2 "Blinking" 1 "On" 0 "Off" ;
VAL_ 2147522816 Joystick3Lamp2Command 3 "Not available or not installed" 2 "Blinking" 1 "On" 0 "Off" ;
VAL_ 2147522816 Joystick3Lamp3Command 3 "Not available or not installed" 2 "Blinking" 1 "On" 0 "Off" ;
VAL_ 2147522816 Joystick3Lamp4Command 3 "Not available or not installed" 2 "Blinking" 1 "On" 0 "Off" ;
VAL_ 2147522816 Joystick3Lamp5Command 3 "Not available or not installed" 2 "Blinking" 1 "On" 0 "Off" ;
VAL_ 2147522816 Joystick3Lamp6Command 3 "Not available or not installed" 2 "Blinking" 1 "On" 0 "Off" ;
VAL_ 2147522816 Joystick3Lamp7Command 3 "Not available or not installed" 2 "Blinking" 1 "On" 0 "Off" ;
VAL_ 2147522816 Joystick3Lamp8Command 3 "Not available or not installed" 2 "Blinking" 1 "On" 0 "Off" ;
VAL_ 2147522816 Joystick3Lamp9Command 3 "Not available or not installed" 2 "Blinking" 1 "On" 0 "Off" ;
VAL_ 2147522816 Joystick3Lamp10Command 3 "Not available or not installed" 2 "Blinking" 1 "On" 0 "Off" ;
VAL_ 2147548899 SupportVariableRateTSC1Message 8 "Reserved for SAE assignment" 7 "20 ms transmission rate" 6 "50 ms transmission rate" 5 "100 ms transmission rate" 4 "250 ms transmission rate" 3 "500 ms transmission rate" 2 "750 ms transmission rate" 1 "1000 ms transmission rate" ;
